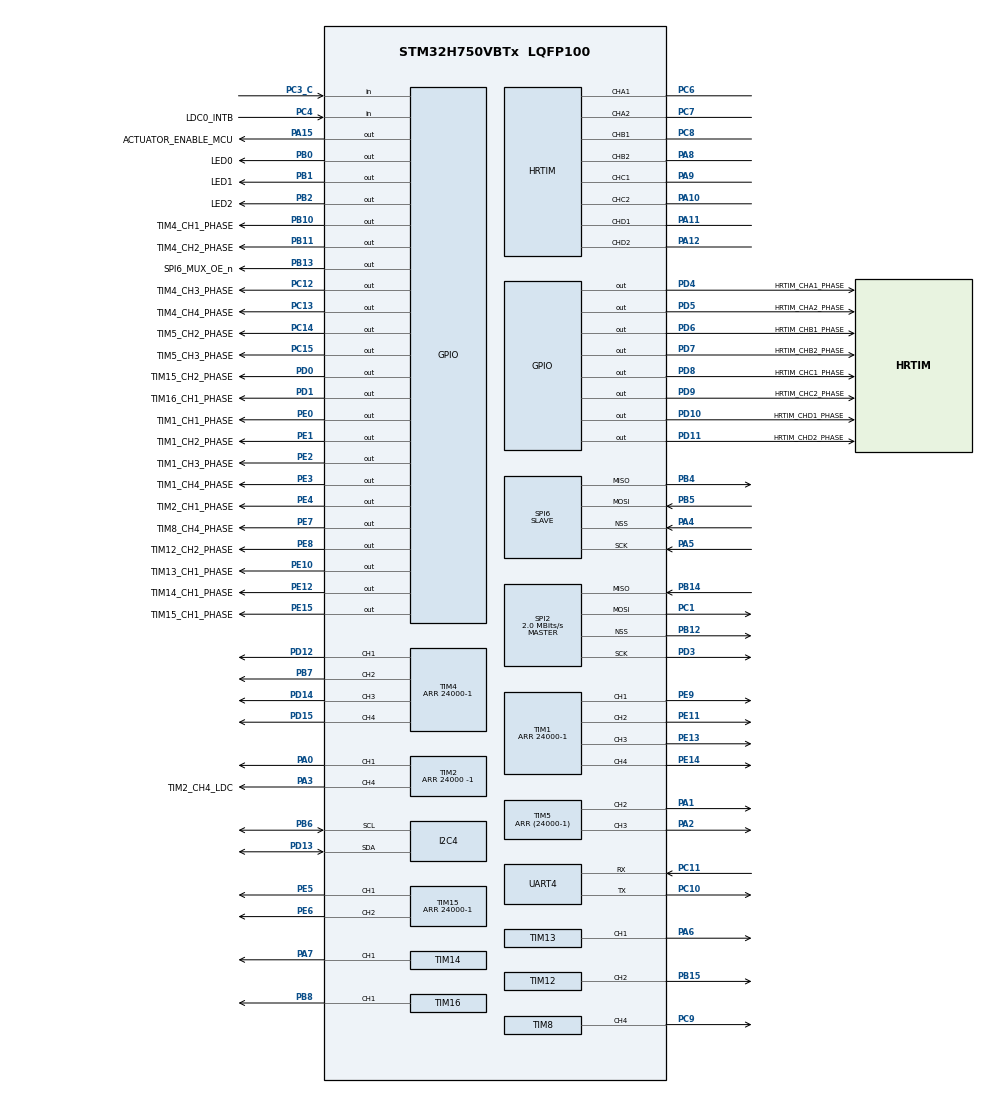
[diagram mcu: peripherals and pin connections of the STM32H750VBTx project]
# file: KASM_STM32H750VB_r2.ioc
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CRC.CRCLength=CRC_POLYLENGTH_16B
CRC.DefaultInitValueUse=DEFAULT_INIT_VALUE_DISABLE
CRC.DefaultPolynomialUse=DEFAULT_POLYNOMIAL_DISABLE
HRTIM.CompareUnit1-Output_TA1TA2=HRTIM_COMPAREUNIT_1
HRTIM.CompareUnit1-Output_TB1TB2=HRTIM_COMPAREUNIT_1
HRTIM.CompareUnit1-Output_TC1TC2=HRTIM_COMPAREUNIT_1
HRTIM.CompareUnit1-Output_TD1TD2=HRTIM_COMPAREUNIT_1
HRTIM.CompareUnit2-Output_TA1TA2=HRTIM_COMPAREUNIT_2
HRTIM.CompareUnit2-Output_TB1TB2=HRTIM_COMPAREUNIT_2
HRTIM.CompareUnit2-Output_TC1TC2=HRTIM_COMPAREUNIT_2
HRTIM.CompareUnit2-Output_TD1TD2=HRTIM_COMPAREUNIT_2
HRTIM.CompareValue1-Output_TA1TA2=(24000-1)/1000
HRTIM.CompareValue1-Output_TB1TB2=(24000-1)/1000
HRTIM.CompareValue1-Output_TC1TC2=(24000 -1)/1000
HRTIM.CompareValue1-Output_TD1TD2=(24000-1)/1000
HRTIM.CompareValue2-Output_TA1TA2=(24000-1)/1000
HRTIM.CompareValue2-Output_TB1TB2=(24000-1)/1000
HRTIM.CompareValue2-Output_TC1TC2=(24000-1)/1000
HRTIM.CompareValue2-Output_TD1TD2=(24000-1)/1000
HRTIM.Configuration_TD=Waveform
HRTIM.Event_EEV1=HRTIM_EVENT_1
HRTIM.NumberResetSource1-Output_TA1TA2=1
HRTIM.NumberResetSource1-Output_TB1TB2=1
HRTIM.NumberResetSource1-Output_TC1TC2=1
HRTIM.NumberResetSource1-Output_TD1TD2=1
HRTIM.NumberResetSource2_TA=1
HRTIM.NumberResetSource2_TB=1
HRTIM.NumberResetSource2_TC=1
HRTIM.NumberResetSource2_TD=1
HRTIM.NumberResetTrigger-Output_TA1TA2=1
HRTIM.NumberResetTrigger-Output_TB1TB2=1
HRTIM.NumberResetTrigger-Output_TC1TC2=1
HRTIM.NumberResetTrigger-Output_TD1TD2=1
HRTIM.NumberSetSource1-Output_TA1TA2=2
HRTIM.NumberSetSource1-Output_TB1TB2=2
HRTIM.NumberSetSource1-Output_TC1TC2=2
HRTIM.NumberSetSource1-Output_TD1TD2=1
HRTIM.NumberSetSource2_TA=2
HRTIM.NumberSetSource2_TB=2
HRTIM.NumberSetSource2_TC=1
HRTIM.NumberSetSource2_TD=1
HRTIM.NumberUpdateTrigger-Output_TA1TA2=0
HRTIM.Periode_TA=24000 -1
HRTIM.Periode_TB=24000-1
HRTIM.Periode_TC=24000-1
HRTIM.Periode_TD=24000 -1
HRTIM.PreloadEnable-Output_TA1TA2=HRTIM_PRELOAD_ENABLED
HRTIM.PreloadEnable-Output_TB1TB2=HRTIM_PRELOAD_ENABLED
HRTIM.PreloadEnable-Output_TC1TC2=HRTIM_PRELOAD_ENABLED
HRTIM.PreloadEnable-Output_TD1TD2=HRTIM_PRELOAD_ENABLED
HRTIM.PrescalerRatio_TA=HRTIM_PRESCALERRATIO_DIV1
HRTIM.ResetOutput1_Source1-Output_TA1TA2=HRTIM_OUTPUTRESET_TIMCMP1
HRTIM.ResetOutput1_Source1-Output_TB1TB2=HRTIM_OUTPUTRESET_TIMCMP1
HRTIM.ResetOutput1_Source1-Output_TC1TC2=HRTIM_OUTPUTRESET_TIMCMP1
HRTIM.ResetOutput1_Source1-Output_TD1TD2=HRTIM_OUTPUTRESET_TIMCMP1
HRTIM.ResetOutput2_Source1-Output_TA1TA2=HRTIM_OUTPUTRESET_TIMCMP2
HRTIM.ResetOutput2_Source1-Output_TB1TB2=HRTIM_OUTPUTRESET_TIMCMP2
HRTIM.ResetOutput2_Source1-Output_TC1TC2=HRTIM_OUTPUTRESET_TIMCMP2
HRTIM.ResetOutput2_Source1-Output_TD1TD2=HRTIM_OUTPUTRESET_TIMCMP2
HRTIM.ResetTrigger1-Output_TA1TA2=HRTIM_TIMRESETTRIGGER_EEV_1
HRTIM.ResetTrigger1-Output_TB1TB2=HRTIM_TIMRESETTRIGGER_EEV_1
HRTIM.ResetTrigger1-Output_TC1TC2=HRTIM_TIMRESETTRIGGER_EEV_1
HRTIM.ResetTrigger1-Output_TD1TD2=HRTIM_TIMRESETTRIGGER_EEV_1
HRTIM.ResetUpdate-Output_TA1TA2=HRTIM_TIMUPDATEONRESET_ENABLED
HRTIM.ResetUpdate-Output_TB1TB2=HRTIM_TIMUPDATEONRESET_ENABLED
HRTIM.ResetUpdate-Output_TC1TC2=HRTIM_TIMUPDATEONRESET_ENABLED
HRTIM.ResetUpdate-Output_TD1TD2=HRTIM_TIMUPDATEONRESET_ENABLED
HRTIM.Sensitivity_EEV1=HRTIM_EVENTSENSITIVITY_RISINGEDGE
HRTIM.SetOutput1_Source1-Output_TA1TA2=HRTIM_OUTPUTSET_EEV_1
HRTIM.SetOutput1_Source1-Output_TB1TB2=HRTIM_OUTPUTSET_RESYNC
HRTIM.SetOutput1_Source1-Output_TC1TC2=HRTIM_OUTPUTSET_TIMPER
HRTIM.SetOutput1_Source1-Output_TD1TD2=HRTIM_OUTPUTSET_TIMPER
HRTIM.SetOutput1_Source2-Output_TA1TA2=HRTIM_OUTPUTSET_TIMPER
HRTIM.SetOutput1_Source2-Output_TB1TB2=HRTIM_OUTPUTSET_TIMPER
HRTIM.SetOutput1_Source2-Output_TC1TC2=HRTIM_OUTPUTSET_RESYNC
HRTIM.SetOutput2_Source1-Output_TA1TA2=HRTIM_OUTPUTSET_TIMPER
HRTIM.SetOutput2_Source1-Output_TB1TB2=HRTIM_OUTPUTSET_RESYNC
HRTIM.SetOutput2_Source1-Output_TC1TC2=HRTIM_OUTPUTSET_TIMPER
HRTIM.SetOutput2_Source1-Output_TD1TD2=HRTIM_OUTPUTSET_TIMPER
HRTIM.SetOutput2_Source2-Output_TA1TA2=HRTIM_OUTPUTSET_EEV_1
HRTIM.SetOutput2_Source2-Output_TB1TB2=HRTIM_OUTPUTSET_TIMPER
HRTIM.Source_EEV1=HRTIM_EVENTSRC_3
I2C4.Timing=0x307075B1
Mcu.Family=STM32H7
Mcu.Name=STM32H750VBTx
Mcu.Package=LQFP100
NVIC.PriorityGroup=NVIC_PRIORITYGROUP_4
NVIC.SPI6_IRQn=true\:1\:0\:true\:false\:true\:true\:true\:true
NVIC.TIM1_UP_IRQn=true\:0\:0\:false\:false\:true\:true\:true\:true
NVIC.UART4_IRQn=true\:2\:0\:true\:false\:true\:true\:true\:true
PA0.Signal=S_TIM2_CH1_ETR
PA1.Signal=S_TIM5_CH2
PA10.Mode=Output_TC1TC2
PA10.Signal=HRTIM_CHC2
PA11.Mode=Output_TD1TD2
PA11.Signal=HRTIM_CHD1
PA12.Mode=Output_TD1TD2
PA12.Signal=HRTIM_CHD2
PA13\ (JTMS/SWDIO).Mode=Trace_Asynchronous_SW
PA13\ (JTMS/SWDIO).Signal=DEBUG_JTMS-SWDIO
PA14\ (JTCK/SWCLK).Mode=Trace_Asynchronous_SW
PA14\ (JTCK/SWCLK).Signal=DEBUG_JTCK-SWCLK
PA15\ (JTDI).GPIO_Label=ACTUATOR_ENABLE_MCU
PA15\ (JTDI).Signal=GPIO_Output
PA2.Signal=S_TIM5_CH3
PA3.GPIO_Label=TIM2_CH4_LDC
PA3.Signal=S_TIM2_CH4
PA4.Mode=NSS_Signal_Hard_Input
PA4.Signal=SPI6_NSS
PA5.Mode=Full_Duplex_Slave
PA5.Signal=SPI6_SCK
PA6.Signal=S_TIM13_CH1
PA7.Signal=S_TIM14_CH1
PA8.Mode=Output_TB1TB2
PA8.Signal=HRTIM_CHB2
PA9.Mode=Output_TC1TC2
PA9.Signal=HRTIM_CHC1
PB0.GPIO_Label=LED0
PB0.Signal=GPIO_Output
PB1.GPIO_Label=LED1
PB1.Signal=GPIO_Output
PB10.GPIO_Label=TIM4_CH1_PHASE
PB10.Signal=GPIO_Output
PB11.GPIO_Label=TIM4_CH2_PHASE
PB11.Signal=GPIO_Output
PB12.Mode=NSS_Signal_Hard_Output
PB12.Signal=SPI2_NSS
PB13.GPIO_Label=SPI6_MUX_OE_n
PB13.Signal=GPIO_Output
PB14.Mode=Full_Duplex_Master
PB14.Signal=SPI2_MISO
PB15.Signal=S_TIM12_CH2
PB2.GPIO_Label=LED2
PB2.Signal=GPIO_Output
PB3\ (JTDO/TRACESWO).Mode=Trace_Asynchronous_SW
PB3\ (JTDO/TRACESWO).Signal=DEBUG_JTDO-SWO
PB4\ (NJTRST).Mode=Full_Duplex_Slave
PB4\ (NJTRST).Signal=SPI6_MISO
PB5.Mode=Full_Duplex_Slave
PB5.Signal=SPI6_MOSI
PB6.Mode=I2C
PB6.Signal=I2C4_SCL
PB7.Signal=S_TIM4_CH2
PB8.Signal=S_TIM16_CH1
PC0.Signal=ADCx_INP10
PC1.Mode=Full_Duplex_Master
PC1.Signal=SPI2_MOSI
PC10.Mode=Asynchronous
PC10.Signal=UART4_TX
PC11.Mode=Asynchronous
PC11.Signal=UART4_RX
PC12.GPIO_Label=TIM4_CH3_PHASE
PC12.Signal=GPIO_Output
PC13.GPIO_Label=TIM4_CH4_PHASE
PC13.Signal=GPIO_Output
PC14-OSC32_IN\ (OSC32_IN).GPIO_Label=TIM5_CH2_PHASE
PC14-OSC32_IN\ (OSC32_IN).Signal=GPIO_Output
PC15-OSC32_OUT\ (OSC32_OUT).GPIO_Label=TIM5_CH3_PHASE
PC15-OSC32_OUT\ (OSC32_OUT).Signal=GPIO_Output
PC3_C.Signal=GPIO_Input
PC4.GPIO_Label=LDC0_INTB
PC4.Signal=GPIO_Input
PC6.Mode=Output_TA1TA2
PC6.Signal=HRTIM_CHA1
PC7.Mode=Output_TA1TA2
PC7.Signal=HRTIM_CHA2
PC8.Mode=Output_TB1TB2
PC8.Signal=HRTIM_CHB1
PC9.Signal=S_TIM8_CH4
PD0.GPIO_Label=TIM15_CH2_PHASE
PD0.Signal=GPIO_Output
PD1.GPIO_Label=TIM16_CH1_PHASE
PD1.Signal=GPIO_Output
PD10.GPIO_Label=HRTIM_CHD1_PHASE
PD10.Signal=GPIO_Output
PD11.GPIO_Label=HRTIM_CHD2_PHASE
PD11.Signal=GPIO_Output
PD12.Signal=S_TIM4_CH1
PD13.Mode=I2C
PD13.Signal=I2C4_SDA
PD14.Signal=S_TIM4_CH3
PD15.Signal=S_TIM4_CH4
PD3.Mode=Full_Duplex_Master
PD3.Signal=SPI2_SCK
PD4.GPIO_Label=HRTIM_CHA1_PHASE
PD4.Signal=GPIO_Output
PD5.GPIO_Label=HRTIM_CHA2_PHASE
PD5.Signal=GPIO_Output
PD6.GPIO_Label=HRTIM_CHB1_PHASE
PD6.Signal=GPIO_Output
PD7.GPIO_Label=HRTIM_CHB2_PHASE
PD7.Signal=GPIO_Output
PD8.GPIO_Label=HRTIM_CHC1_PHASE
PD8.Signal=GPIO_Output
PD9.GPIO_Label=HRTIM_CHC2_PHASE
PD9.Signal=GPIO_Output
PE0.GPIO_Label=TIM1_CH1_PHASE
PE0.Signal=GPIO_Output
PE1.GPIO_Label=TIM1_CH2_PHASE
PE1.Signal=GPIO_Output
PE10.GPIO_Label=TIM13_CH1_PHASE
PE10.Signal=GPIO_Output
PE11.Signal=S_TIM1_CH2
PE12.GPIO_Label=TIM14_CH1_PHASE
PE12.Signal=GPIO_Output
PE13.Signal=S_TIM1_CH3
PE14.Signal=S_TIM1_CH4
PE15.GPIO_Label=TIM15_CH1_PHASE
PE15.Signal=GPIO_Output
PE2.GPIO_Label=TIM1_CH3_PHASE
PE2.Signal=GPIO_Output
PE3.GPIO_Label=TIM1_CH4_PHASE
PE3.Signal=GPIO_Output
PE4.GPIO_Label=TIM2_CH1_PHASE
PE4.Signal=GPIO_Output
PE5.Signal=S_TIM15_CH1
PE6.Signal=S_TIM15_CH2
PE7.GPIO_Label=TIM8_CH4_PHASE
PE7.Signal=GPIO_Output
PE8.GPIO_Label=TIM12_CH2_PHASE
PE8.Signal=GPIO_Output
PE9.Signal=S_TIM1_CH1
PH0-OSC_IN\ (PH0).Mode=HSE-External-Oscillator
PH0-OSC_IN\ (PH0).Signal=RCC_OSC_IN
PH1-OSC_OUT\ (PH1).Mode=HSE-External-Oscillator
PH1-OSC_OUT\ (PH1).Signal=RCC_OSC_OUT
ProjectManager.HeapSize=0x200
ProjectManager.StackSize=0x400
ProjectManager.TargetToolchain=STM32CubeIDE
RCC.ADCFreq_Value=75000000
RCC.APB1Freq_Value=120000000
RCC.APB2Freq_Value=120000000
RCC.APB3Freq_Value=120000000
RCC.APB4Freq_Value=120000000
RCC.CortexFreq_Value=480000000
RCC.D1PPRE=RCC_APB3_DIV2
RCC.D2PPRE1=RCC_APB1_DIV2
RCC.D2PPRE2=RCC_APB2_DIV2
RCC.D3PPRE=RCC_APB4_DIV2
RCC.DIVM1=2
RCC.DIVM2=2
RCC.DIVN1=80
RCC.DIVN2=12
RCC.DIVQ1=15
RCC.HCLKFreq_Value=240000000
RCC.HPRE=RCC_HCLK_DIV2
RCC.HSE_VALUE=24000000
RCC.PLL2FRACN=4096
RCC.PLL3FRACN=0
RCC.PLLFRACN=0
RCC.PLLSourceVirtual=RCC_PLLSOURCE_HSE
RCC.SYSCLKFreq_VALUE=480000000
RCC.SYSCLKSource=RCC_SYSCLKSOURCE_PLLCLK
RCC.USBFreq_Value=64000000
SH.ADCx_INP10.0=ADC2_INP10
SH.S_TIM12_CH2.0=TIM12_CH2,PWM Generation2 CH2
SH.S_TIM13_CH1.0=TIM13_CH1,PWM Generation1 CH1
SH.S_TIM14_CH1.0=TIM14_CH1,PWM Generation1 CH1
SH.S_TIM15_CH1.0=TIM15_CH1,PWM Generation1 CH1
SH.S_TIM15_CH2.0=TIM15_CH2,PWM Generation2 CH2
SH.S_TIM16_CH1.0=TIM16_CH1,PWM Generation1 CH1
SH.S_TIM1_CH1.0=TIM1_CH1,PWM Generation1 CH1
SH.S_TIM1_CH2.0=TIM1_CH2,PWM Generation2 CH2
SH.S_TIM1_CH3.0=TIM1_CH3,PWM Generation3 CH3
SH.S_TIM1_CH4.0=TIM1_CH4,PWM Generation4 CH4
SH.S_TIM2_CH1_ETR.0=TIM2_CH1,PWM Generation1 CH1
SH.S_TIM2_CH4.0=TIM2_CH4,PWM Generation4 CH4
SH.S_TIM4_CH1.0=TIM4_CH1,PWM Generation1 CH1
SH.S_TIM4_CH2.0=TIM4_CH2,PWM Generation2 CH2
SH.S_TIM4_CH3.0=TIM4_CH3,PWM Generation3 CH3
SH.S_TIM4_CH4.0=TIM4_CH4,PWM Generation4 CH4
SH.S_TIM5_CH2.0=TIM5_CH2,PWM Generation2 CH2
SH.S_TIM5_CH3.0=TIM5_CH3,PWM Generation3 CH3
SH.S_TIM8_CH4.0=TIM8_CH4,PWM Generation4 CH4
SPI2.BaudRatePrescaler=SPI_BAUDRATEPRESCALER_32
SPI2.CalculateBaudRate=2.0 MBits/s
SPI2.DataSize=SPI_DATASIZE_8BIT
SPI2.Direction=SPI_DIRECTION_2LINES
SPI2.Mode=SPI_MODE_MASTER
SPI2.VirtualNSS=VM_NSSHARD
SPI2.VirtualType=VM_MASTER
SPI6.DataSize=SPI_DATASIZE_8BIT
SPI6.Direction=SPI_DIRECTION_2LINES
SPI6.Mode=SPI_MODE_SLAVE
SPI6.VirtualNSS=VM_NSSHARD
SPI6.VirtualType=VM_SLAVE
TIM1.AutoReloadPreload=TIM_AUTORELOAD_PRELOAD_ENABLE
TIM1.Channel-PWM\ Generation1\ CH1=TIM_CHANNEL_1
TIM1.Channel-PWM\ Generation2\ CH2=TIM_CHANNEL_2
TIM1.Channel-PWM\ Generation3\ CH3=TIM_CHANNEL_3
TIM1.Channel-PWM\ Generation4\ CH4=TIM_CHANNEL_4
TIM1.Period=24000-1
TIM1.Pulse-PWM\ Generation1\ CH1=(24000-1)/1000
TIM1.Pulse-PWM\ Generation2\ CH2=(24000-1)/1000
TIM1.Pulse-PWM\ Generation3\ CH3=(24000-1)/1000
TIM1.Pulse-PWM\ Generation4\ CH4=(24000-1)/1000
TIM1.TIM_MasterOutputTrigger=TIM_TRGO_UPDATE
TIM1.TIM_MasterSlaveMode=TIM_MASTERSLAVEMODE_ENABLE
TIM12.AutoReloadPreload=TIM_AUTORELOAD_PRELOAD_ENABLE
TIM12.Channel-PWM\ Generation2\ CH2=TIM_CHANNEL_2
TIM12.Period=24000-1
TIM12.Pulse-PWM\ Generation2\ CH2=(24000-1)/1000
TIM13.Channel=TIM_CHANNEL_1
TIM13.Period=24000-1
TIM13.Pulse=(24000-1)/1000
TIM14.Channel=TIM_CHANNEL_1
TIM14.Period=24000-1
TIM14.Pulse=(24000-1)/1000
TIM15.Channel-PWM\ Generation1\ CH1=TIM_CHANNEL_1
TIM15.Channel-PWM\ Generation2\ CH2=TIM_CHANNEL_2
TIM15.Period=24000-1
TIM15.Pulse-PWM\ Generation1\ CH1=(24000-1)/1000
TIM15.Pulse-PWM\ Generation2\ CH2=(24000-1)/1000
TIM16.Channel=TIM_CHANNEL_1
TIM16.Period=24000-1
TIM16.Pulse=(24000-1)/1000
TIM2.Channel-PWM\ Generation1\ CH1=TIM_CHANNEL_1
TIM2.Channel-PWM\ Generation4\ CH4=TIM_CHANNEL_4
TIM2.Period=24000 -1
TIM2.Pulse-PWM\ Generation1\ CH1=(24000 -1)/1000
TIM2.Pulse-PWM\ Generation4\ CH4=(24000-1)/1000
TIM4.Channel-PWM\ Generation1\ CH1=TIM_CHANNEL_1
TIM4.Channel-PWM\ Generation2\ CH2=TIM_CHANNEL_2
TIM4.Channel-PWM\ Generation3\ CH3=TIM_CHANNEL_3
TIM4.Channel-PWM\ Generation4\ CH4=TIM_CHANNEL_4
TIM4.Period=24000-1
TIM4.Pulse-PWM\ Generation1\ CH1=(24000 -1)/1000
TIM4.Pulse-PWM\ Generation2\ CH2=(24000-1)/1000
TIM4.Pulse-PWM\ Generation3\ CH3=(24000-1)/1000
TIM4.Pulse-PWM\ Generation4\ CH4=(24000-1)/1000
TIM4.TIM_MasterOutputTrigger=TIM_TRGO_UPDATE
TIM5.AutoReloadPreload=TIM_AUTORELOAD_PRELOAD_ENABLE
TIM5.Channel-PWM\ Generation2\ CH2=TIM_CHANNEL_2
TIM5.Channel-PWM\ Generation3\ CH3=TIM_CHANNEL_3
TIM5.Period=(24000-1)
TIM5.Pulse-PWM\ Generation2\ CH2=(24000-1)/1000
TIM5.Pulse-PWM\ Generation3\ CH3=(24000-1)/1000
TIM8.AutoReloadPreload=TIM_AUTORELOAD_PRELOAD_ENABLE
TIM8.Channel-PWM\ Generation4\ CH4=TIM_CHANNEL_4
TIM8.Period=24000 -1
TIM8.Pulse-PWM\ Generation4\ CH4=(24000-1)/1000
UART4.FIFOMode=FIFOMODE_DISABLE
VP_CRC_VS_CRC.Mode=CRC_Activate
VP_LPTIM1_VS_LPTIM_counterModeInternalClock.Mode=Counts__internal_clock_event_00
VP_LPTIM2_VS_LPTIM_counterModeInternalClock.Mode=Counts__internal_clock_event_00
VP_LPTIM3_VS_LPTIM_counterModeInternalClock.Mode=Counts__internal_clock_event_00
VP_MEMORYMAP_VS_MEMORYMAP.Mode=CurAppReg
VP_TIM12_VS_ClockSourceITR.Mode=TriggerSource_ITR0
VP_TIM12_VS_ControllerModeReset.Mode=Reset Mode
VP_TIM13_VS_ClockSourceINT.Mode=Enable_Timer
VP_TIM14_VS_ClockSourceINT.Mode=Enable_Timer
VP_TIM15_VS_ClockSourceITR.Mode=TriggerSource_ITR0
VP_TIM15_VS_ControllerModeReset.Mode=Reset Mode
VP_TIM16_VS_ClockSourceINT.Mode=Enable_Timer
VP_TIM1_VS_ClockSourceINT.Mode=Internal
VP_TIM4_VS_ClockSourceINT.Mode=Internal
VP_TIM4_VS_ClockSourceITR.Mode=TriggerSource_ITR0
VP_TIM4_VS_ControllerModeReset.Mode=Reset Mode
VP_TIM5_VS_ClockSourceITR.Mode=TriggerSource_ITR0
VP_TIM5_VS_ControllerModeReset.Mode=Reset Mode
VP_TIM8_VS_ClockSourceITR.Mode=TriggerSource_ITR0
VP_TIM8_VS_ControllerModeReset.Mode=Reset Mode
board=custom

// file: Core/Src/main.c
/* USER CODE BEGIN Header */
/**
  ******************************************************************************
  * @file           : main.c
  * @brief          : Main program body
  ******************************************************************************
  * @attention
  *
  * Copyright (c) 2025 STMicroelectronics.
  * All rights reserved.
  *
  * This software is licensed under terms that can be found in the LICENSE file
  * in the root directory of this software component.
  * If no LICENSE file comes with this software, it is provided AS-IS.
  *
  ******************************************************************************
  */
/* USER CODE END Header */
#include "main.h"

/* USER CODE BEGIN Includes */
#include "circular_buffer.h"
#include "actuators.h"
#include "stdio.h"
#include "stdlib.h"
#include "string.h"

/* USER CODE END Includes */

/* USER CODE BEGIN PD */

#define TRUE 1
#define FALSE 0
#define BUFFER_SIZE 80
#define MINDUTYCYCLE 20
#define PERIOD (24000-1)
#define MAXDUTYCYCLE PERIOD
#define MICRON_1 1000
#define MICRON_10 10000
#define CMD_VEC_LENGTH (NUM_ACTUATORS * 2)
#define CMD_HDR_LENGTH 3
#define END1 0xe1
#define END2 0xe2
#define SPI_BUFFER_SIZE 1000
#define SPI_TICKS 10000
#define SPI_MSG_SIZE 54

/* USER CODE END PD */

CRC_HandleTypeDef hcrc;

HRTIM_HandleTypeDef hhrtim;

I2C_HandleTypeDef hi2c4;

LPTIM_HandleTypeDef hlptim1;
LPTIM_HandleTypeDef hlptim2;
LPTIM_HandleTypeDef hlptim3;

SPI_HandleTypeDef hspi2;
SPI_HandleTypeDef hspi6;

TIM_HandleTypeDef htim1;
TIM_HandleTypeDef htim2;
TIM_HandleTypeDef htim4;
TIM_HandleTypeDef htim5;
TIM_HandleTypeDef htim8;
TIM_HandleTypeDef htim12;
TIM_HandleTypeDef htim13;
TIM_HandleTypeDef htim14;
TIM_HandleTypeDef htim15;
TIM_HandleTypeDef htim16;

/* USER CODE BEGIN PV */

/* UART transmit and receive buffers */
circular_buffer_t rxbuf; /* UART receive buffer */
circular_buffer_t txbuf; /* UART transmit buffer */
circular_buffer_t *rxbuf_p = &rxbuf; /* UART receive buffer pointer */
circular_buffer_t *txbuf_p = &txbuf; /* UART transmit buffer pointer */

/* UART flags and signals */
int msg_recvd = FALSE;
//char msg_buffer[BUFFER_LENGTH];
int reading_rx_buffer = FALSE;
int writing_tx_buffer = FALSE;
int tx_collision = FALSE;
int rx_collision = FALSE;
volatile int rx_collision_count = 0;
volatile int tx_collision_count = 0;
volatile int cbuf_write_err = FALSE;

/* SPI circular RX buffer */
circular_buffer_t spirx_cbuf;
circular_buffer_t* spirx_cbuf_p = &spirx_cbuf; // buffer handle pointer

/* SPI test message and buffers */
uint8_t SPI_TX_buffer[SPI_MSG_SIZE] = {0};
uint8_t SPI_RX_buffer[SPI_BUFFER_SIZE] = {0};

/* SPI flags and signals */
int spi_packet_rcvd = FALSE;
int spi_counter_expired = FALSE;

/* Period timer flag */
uint32_t tick_counter = 0;  // use the period counter as a clock
uint8_t ctrl_tmr_expired = FALSE;

/* Command reference vector */
union command {
	int16_t vals[NUM_ACTUATORS];  //displacement commands in nanometers
	uint8_t bytes[NUM_ACTUATORS *2];  // byte equivalents
} reference;
union command* ref_p = &reference;

static int16_t cmd_ref[NUM_ACTUATORS] = {0};  //displacement commands in nanometers

/* TODO */
/* We need the actual bytes to transmit, not the short ints-->either set up a union, or calculate the bytes externally */
static int16_t rnd_vals[NUM_ACTUATORS] = {-850, -50, 922, -10000, -895, 29, 175, 586, 259, 232, 381, -190, 447, 163, -1012, 863, 619, -861, 213, 390, -83, 592, 903, -845, 313, -833};  //random displacement commands in nanometers

uint8_t cmd_bytes[NUM_ACTUATORS * 2] = {0};
uint8_t new_cmd_ready = FALSE;

/* actuators */
actuator_t actuators[NUM_ACTUATORS];

typedef enum serial_receive_state_t{
	STORE_BYTE,
	CHECK_FOR_END
}serial_receive_state_t;

uint16_t test_data[2] = {0};

/* USER CODE END PV */

void SystemClock_Config(void);
static void MX_GPIO_Init(void);
static void MX_HRTIM_Init(void);
static void MX_I2C4_Init(void);
static void MX_LPTIM1_Init(void);
static void MX_LPTIM2_Init(void);
static void MX_LPTIM3_Init(void);
static void MX_SPI2_Init(void);
static void MX_TIM1_Init(void);
static void MX_TIM2_Init(void);
static void MX_TIM4_Init(void);
static void MX_TIM5_Init(void);
static void MX_TIM8_Init(void);
static void MX_TIM12_Init(void);
static void MX_TIM13_Init(void);
static void MX_TIM14_Init(void);
static void MX_TIM15_Init(void);
static void MX_TIM16_Init(void);
static void MX_UART4_Init(void);
static void MX_SPI6_Init(void);
static void MX_CRC_Init(void);
/* USER CODE BEGIN PFP */

/**
 * @function : UART_parse_message
 * @brief : reads the message from the rx buffer and puts it into module level message buffer
 * @param :  none
 * @return : none
 * @author : Aaron Hunter
 */
static void UART_parse_message();

/**
 * @function : UART_print(char* buf, int length)
 * @brief : writes a buffer to the tx_buffer and triggers a UART TX
 * @param : buffer pointer
 * @param : buffer length
 * @return : none
 * @author : Aaron Hunter
 */
static void UART_print(char* buf, int length);

/**
 * @function : init_channels
 * @brief : initializes all the PWM channels
 * @param :  none
 * @return : none
 * @author : Aaron Hunter
 */
static void init_channels(void);

/**
 * @function : init_actuators
 * @brief : Creates and populates actuator array
 * @param :  none
 * @return : none
 * @author : Aaron Hunter
 */
static void init_actuators(void);

/**
 * @function : update_commands
 * @brief : sets the new actuator command targets
 * @return none
 * @author Aaron Hunter
 */
static void update_commands(void);

/**
 * @function calc_dutycycle(cmd)
 * @param cmd
 * @return dutycycle
 * @authoer Aaron Hunter
 */
uint16_t calc_dutycycle(int16_t cmd);

/**
 * @function : run_RX_state_machine
 * @brief : parses external command messages
 * @param byte : received byte
 * @return none
 * @author Aaron Hunter
 * */
void run_RX_state_machine(uint8_t byte);

/**
 * @function : run_SPI_RX_state_machine
 * @brief : parses external SPI command messages
 * @param byte : received byte
 * @return none
 * @author Aaron Hunter
 * */
void run_SPI_RX_state_machine(uint8_t byte);

/* USER CODE END PFP */

int main(void)
{

  /* USER CODE BEGIN 1 */

	/* init all actuators to a small displacement */
	int i = {0};
	for(i = 0; i < NUM_ACTUATORS; i++){
		reference.vals[i] = MICRON_10;
	}
	new_cmd_ready = TRUE; // tell main to update the actuator dutycycles

	test_data[0] = 0xdead;
	test_data[1] = 0xbeef;
  /* USER CODE END 1 */

  /* MCU Configuration--------------------------------------------------------*/

  /* Reset of all peripherals, Initializes the Flash interface and the Systick. */
  HAL_Init();

  /* USER CODE BEGIN Init */

  /* initialize the circular buffers */
  init_buffer(rxbuf_p);
  init_buffer(txbuf_p);
  init_buffer(spirx_cbuf_p);

  /* USER CODE END Init */

  /* Configure the system clock */
  SystemClock_Config();

  /* Initialize all configured peripherals */
  MX_GPIO_Init();
  MX_HRTIM_Init();
  MX_I2C4_Init();
  MX_LPTIM1_Init();
  MX_LPTIM2_Init();
  MX_LPTIM3_Init();
  MX_SPI2_Init();
  MX_TIM1_Init();
  MX_TIM2_Init();
  MX_TIM4_Init();
  MX_TIM5_Init();
  MX_TIM8_Init();
  MX_TIM12_Init();
  MX_TIM13_Init();
  MX_TIM14_Init();
  MX_TIM15_Init();
  MX_TIM16_Init();
  MX_UART4_Init();
  MX_SPI6_Init();
  MX_CRC_Init();
  /* USER CODE BEGIN 2 */

  init_channels(); // start PWM generation
  init_actuators(); // set up the actuators
  HAL_GPIO_WritePin(ACTUATOR_ENABLE_MCU_GPIO_Port, ACTUATOR_ENABLE_MCU_Pin, GPIO_PIN_SET); // Turn on actuator power

  /* Say hello to the outside world */
  uint8_t msg[BUFFER_SIZE];
  int msg_length = 0;
  msg_length = sprintf((char *) msg,"KASM Application Starting \r\n");
  UART_print((char *) msg, msg_length);

  SPI_TX_buffer[0] = 0xaa;
  HAL_SPI_TransmitReceive_IT(&hspi6, SPI_TX_buffer, SPI_RX_buffer, SPI_MSG_SIZE);

  /* USER CODE END 2 */

  /* Infinite loop */
  /* USER CODE BEGIN WHILE */
  while (1)
  {
	  /* diagnostics for the interrupts to be removed later */
	  HAL_GPIO_WritePin(LED0_GPIO_Port, LED0_Pin,GPIO_PIN_RESET);
	  HAL_GPIO_WritePin(LED2_GPIO_Port, LED2_Pin,GPIO_PIN_RESET);
	  if(msg_recvd == TRUE){
		  UART_parse_message();
		  msg_recvd = FALSE;
	  }

	  if(ctrl_tmr_expired == TRUE){
		  tick_counter++;
		  if (tick_counter % SPI_TICKS == 0) {
			  spi_counter_expired = TRUE;
		  }
		  if( new_cmd_ready == TRUE){ //only update commands on change
			  update_commands();// update command targets
			  new_cmd_ready = FALSE;
		  }
		  ctrl_tmr_expired = FALSE; //reset timer
	  }

	  /* check for errors to the UART circular buffers */
	  if(cbuf_write_err == TRUE){
		  msg_length = sprintf(msg, "Message read error ");
		  UART_print(msg,msg_length);
		  cbuf_write_err = FALSE;
	  }

	  if(spi_packet_rcvd == TRUE){
		  HAL_GPIO_WritePin(LED1_GPIO_Port, LED1_Pin,GPIO_PIN_RESET);

#ifdef SPI_TESTING
		  int i = {0};
		  for(i = 0; i < SPI_MSG_SIZE; i++){
			  msg_length = sprintf((char *) msg,"%x ",SPI_RX_buffer[i]);
			  UART_print((char *) msg, msg_length);
		  }
		  msg_length = sprintf((char *) msg,"\r\n");
		  UART_print((char *) msg, msg_length);
#endif

		  // check crc for transmission errors
		  uint32_t crc_val = HAL_CRC_Calculate(&hcrc, (uint32_t*) &SPI_RX_buffer,SPI_MSG_SIZE/2);

#ifdef SPI_TESTING
		  msg_length = sprintf((char *) msg,"CRC check %x\r\n", crc_val);
		  UART_print((char *) msg, msg_length);
#endif

		  if(crc_val == 0){
			  msg_length = sprintf((char *) msg,"Valid SPI command vector received \r\n");
			  UART_print((char *) msg, msg_length);
			  // copy memory into command vector
			  memcpy(reference.vals, &SPI_RX_buffer, NUM_ACTUATORS*(sizeof(int16_t)));
			  // inform main of a new command
			  new_cmd_ready = TRUE;
		  }

		  // restart SPI bus
		  HAL_SPI_TransmitReceive_IT(&hspi6, SPI_TX_buffer, SPI_RX_buffer, SPI_MSG_SIZE);

		  spi_packet_rcvd = FALSE; // reset SPI packet flag
	  }

    /* USER CODE END WHILE */

  }
}

void SystemClock_Config(void)
{
  RCC_OscInitTypeDef RCC_OscInitStruct = {0};
  RCC_ClkInitTypeDef RCC_ClkInitStruct = {0};

  /** Supply configuration update enable
  */
  HAL_PWREx_ConfigSupply(PWR_LDO_SUPPLY);

  /** Configure the main internal regulator output voltage
  */
  __HAL_PWR_VOLTAGESCALING_CONFIG(PWR_REGULATOR_VOLTAGE_SCALE0);

  while(!__HAL_PWR_GET_FLAG(PWR_FLAG_VOSRDY)) {}

  /** Initializes the RCC Oscillators according to the specified parameters
  * in the RCC_OscInitTypeDef structure.
  */
  RCC_OscInitStruct.OscillatorType = RCC_OSCILLATORTYPE_HSE;
  RCC_OscInitStruct.HSEState = RCC_HSE_ON;
  RCC_OscInitStruct.PLL.PLLState = RCC_PLL_ON;
  RCC_OscInitStruct.PLL.PLLSource = RCC_PLLSOURCE_HSE;
  RCC_OscInitStruct.PLL.PLLM = 2;
  RCC_OscInitStruct.PLL.PLLN = 80;
  RCC_OscInitStruct.PLL.PLLP = 2;
  RCC_OscInitStruct.PLL.PLLQ = 15;
  RCC_OscInitStruct.PLL.PLLR = 2;
  RCC_OscInitStruct.PLL.PLLRGE = RCC_PLL1VCIRANGE_3;
  RCC_OscInitStruct.PLL.PLLVCOSEL = RCC_PLL1VCOWIDE;
  RCC_OscInitStruct.PLL.PLLFRACN = 0;
  if (HAL_RCC_OscConfig(&RCC_OscInitStruct) != HAL_OK)
  {
    Error_Handler();
  }

  /** Initializes the CPU, AHB and APB buses clocks
  */
  RCC_ClkInitStruct.ClockType = RCC_CLOCKTYPE_HCLK|RCC_CLOCKTYPE_SYSCLK
                              |RCC_CLOCKTYPE_PCLK1|RCC_CLOCKTYPE_PCLK2
                              |RCC_CLOCKTYPE_D3PCLK1|RCC_CLOCKTYPE_D1PCLK1;
  RCC_ClkInitStruct.SYSCLKSource = RCC_SYSCLKSOURCE_PLLCLK;
  RCC_ClkInitStruct.SYSCLKDivider = RCC_SYSCLK_DIV1;
  RCC_ClkInitStruct.AHBCLKDivider = RCC_HCLK_DIV2;
  RCC_ClkInitStruct.APB3CLKDivider = RCC_APB3_DIV2;
  RCC_ClkInitStruct.APB1CLKDivider = RCC_APB1_DIV2;
  RCC_ClkInitStruct.APB2CLKDivider = RCC_APB2_DIV2;
  RCC_ClkInitStruct.APB4CLKDivider = RCC_APB4_DIV2;

  if (HAL_RCC_ClockConfig(&RCC_ClkInitStruct, FLASH_LATENCY_4) != HAL_OK)
  {
    Error_Handler();
  }
}

static void MX_CRC_Init(void)
{

  hcrc.Instance = CRC;
  hcrc.Init.DefaultPolynomialUse = DEFAULT_POLYNOMIAL_DISABLE;
  hcrc.Init.DefaultInitValueUse = DEFAULT_INIT_VALUE_DISABLE;
  hcrc.Init.GeneratingPolynomial = 15717;
  hcrc.Init.CRCLength = CRC_POLYLENGTH_16B;
  hcrc.Init.InitValue = 65535;
  hcrc.Init.InputDataInversionMode = CRC_INPUTDATA_INVERSION_NONE;
  hcrc.Init.OutputDataInversionMode = CRC_OUTPUTDATA_INVERSION_DISABLE;
  hcrc.InputDataFormat = CRC_INPUTDATA_FORMAT_HALFWORDS;
  if (HAL_CRC_Init(&hcrc) != HAL_OK)
  {
    Error_Handler();
  }
  /* USER CODE BEGIN CRC_Init 2 */
  hcrc.Instance = CRC;
  hcrc.Init.DefaultPolynomialUse = DEFAULT_POLYNOMIAL_DISABLE;
  hcrc.Init.DefaultInitValueUse = DEFAULT_INIT_VALUE_DISABLE;
  hcrc.Init.GeneratingPolynomial = 15717;
  hcrc.Init.CRCLength = CRC_POLYLENGTH_16B;
  hcrc.Init.InitValue = 65535;
  hcrc.Init.InputDataInversionMode = CRC_INPUTDATA_INVERSION_NONE;
  hcrc.Init.OutputDataInversionMode = CRC_OUTPUTDATA_INVERSION_DISABLE;
  hcrc.InputDataFormat = CRC_INPUTDATA_FORMAT_HALFWORDS;
  if (HAL_CRC_Init(&hcrc) != HAL_OK)
  {
    Error_Handler();
  }

  /* USER CODE END CRC_Init 2 */

}

static void MX_HRTIM_Init(void)
{

  HRTIM_EventCfgTypeDef pEventCfg = {0};
  HRTIM_TimeBaseCfgTypeDef pTimeBaseCfg = {0};
  HRTIM_TimerCfgTypeDef pTimerCfg = {0};
  HRTIM_CompareCfgTypeDef pCompareCfg = {0};
  HRTIM_OutputCfgTypeDef pOutputCfg = {0};

  hhrtim.Instance = HRTIM1;
  hhrtim.Init.HRTIMInterruptResquests = HRTIM_IT_NONE;
  hhrtim.Init.SyncOptions = HRTIM_SYNCOPTION_NONE;
  if (HAL_HRTIM_Init(&hhrtim) != HAL_OK)
  {
    Error_Handler();
  }
  if (HAL_HRTIM_EventPrescalerConfig(&hhrtim, HRTIM_EVENTPRESCALER_DIV1) != HAL_OK)
  {
    Error_Handler();
  }
  pEventCfg.Source = HRTIM_EVENTSRC_3;
  pEventCfg.Polarity = HRTIM_EVENTPOLARITY_HIGH;
  pEventCfg.Sensitivity = HRTIM_EVENTSENSITIVITY_RISINGEDGE;
  pEventCfg.FastMode = HRTIM_EVENTFASTMODE_DISABLE;
  if (HAL_HRTIM_EventConfig(&hhrtim, HRTIM_EVENT_1, &pEventCfg) != HAL_OK)
  {
    Error_Handler();
  }
  pTimeBaseCfg.Period = 24000 -1;
  pTimeBaseCfg.RepetitionCounter = 0x00;
  pTimeBaseCfg.PrescalerRatio = HRTIM_PRESCALERRATIO_DIV1;
  pTimeBaseCfg.Mode = HRTIM_MODE_CONTINUOUS;
  if (HAL_HRTIM_TimeBaseConfig(&hhrtim, HRTIM_TIMERINDEX_TIMER_A, &pTimeBaseCfg) != HAL_OK)
  {
    Error_Handler();
  }
  pTimerCfg.InterruptRequests = HRTIM_TIM_IT_NONE;
  pTimerCfg.DMARequests = HRTIM_TIM_DMA_NONE;
  pTimerCfg.DMASrcAddress = 0x0000;
  pTimerCfg.DMADstAddress = 0x0000;
  pTimerCfg.DMASize = 0x1;
  pTimerCfg.HalfModeEnable = HRTIM_HALFMODE_DISABLED;
  pTimerCfg.StartOnSync = HRTIM_SYNCSTART_DISABLED;
  pTimerCfg.ResetOnSync = HRTIM_SYNCRESET_DISABLED;
  pTimerCfg.DACSynchro = HRTIM_DACSYNC_NONE;
  pTimerCfg.PreloadEnable = HRTIM_PRELOAD_ENABLED;
  pTimerCfg.UpdateGating = HRTIM_UPDATEGATING_INDEPENDENT;
  pTimerCfg.BurstMode = HRTIM_TIMERBURSTMODE_MAINTAINCLOCK;
  pTimerCfg.RepetitionUpdate = HRTIM_UPDATEONREPETITION_DISABLED;
  pTimerCfg.PushPull = HRTIM_TIMPUSHPULLMODE_DISABLED;
  pTimerCfg.FaultEnable = HRTIM_TIMFAULTENABLE_NONE;
  pTimerCfg.FaultLock = HRTIM_TIMFAULTLOCK_READWRITE;
  pTimerCfg.DeadTimeInsertion = HRTIM_TIMDEADTIMEINSERTION_DISABLED;
  pTimerCfg.DelayedProtectionMode = HRTIM_TIMER_A_B_C_DELAYEDPROTECTION_DISABLED;
  pTimerCfg.UpdateTrigger = HRTIM_TIMUPDATETRIGGER_NONE;
  pTimerCfg.ResetTrigger = HRTIM_TIMRESETTRIGGER_EEV_1;
  pTimerCfg.ResetUpdate = HRTIM_TIMUPDATEONRESET_ENABLED;
  if (HAL_HRTIM_WaveformTimerConfig(&hhrtim, HRTIM_TIMERINDEX_TIMER_A, &pTimerCfg) != HAL_OK)
  {
    Error_Handler();
  }
  if (HAL_HRTIM_WaveformTimerConfig(&hhrtim, HRTIM_TIMERINDEX_TIMER_B, &pTimerCfg) != HAL_OK)
  {
    Error_Handler();
  }
  if (HAL_HRTIM_WaveformTimerConfig(&hhrtim, HRTIM_TIMERINDEX_TIMER_C, &pTimerCfg) != HAL_OK)
  {
    Error_Handler();
  }
  pTimerCfg.DelayedProtectionMode = HRTIM_TIMER_D_E_DELAYEDPROTECTION_DISABLED;
  if (HAL_HRTIM_WaveformTimerConfig(&hhrtim, HRTIM_TIMERINDEX_TIMER_D, &pTimerCfg) != HAL_OK)
  {
    Error_Handler();
  }
  pCompareCfg.CompareValue = (24000-1)/1000;
  if (HAL_HRTIM_WaveformCompareConfig(&hhrtim, HRTIM_TIMERINDEX_TIMER_A, HRTIM_COMPAREUNIT_1, &pCompareCfg) != HAL_OK)
  {
    Error_Handler();
  }
  pCompareCfg.AutoDelayedMode = HRTIM_AUTODELAYEDMODE_REGULAR;
  pCompareCfg.AutoDelayedTimeout = 0x0000;

  if (HAL_HRTIM_WaveformCompareConfig(&hhrtim, HRTIM_TIMERINDEX_TIMER_A, HRTIM_COMPAREUNIT_2, &pCompareCfg) != HAL_OK)
  {
    Error_Handler();
  }

  if (HAL_HRTIM_WaveformCompareConfig(&hhrtim, HRTIM_TIMERINDEX_TIMER_B, HRTIM_COMPAREUNIT_2, &pCompareCfg) != HAL_OK)
  {
    Error_Handler();
  }

  if (HAL_HRTIM_WaveformCompareConfig(&hhrtim, HRTIM_TIMERINDEX_TIMER_C, HRTIM_COMPAREUNIT_2, &pCompareCfg) != HAL_OK)
  {
    Error_Handler();
  }

  if (HAL_HRTIM_WaveformCompareConfig(&hhrtim, HRTIM_TIMERINDEX_TIMER_D, HRTIM_COMPAREUNIT_2, &pCompareCfg) != HAL_OK)
  {
    Error_Handler();
  }
  pOutputCfg.Polarity = HRTIM_OUTPUTPOLARITY_HIGH;
  pOutputCfg.SetSource = HRTIM_OUTPUTSET_EEV_1|HRTIM_OUTPUTSET_TIMPER;
  pOutputCfg.ResetSource = HRTIM_OUTPUTRESET_TIMCMP1;
  pOutputCfg.IdleMode = HRTIM_OUTPUTIDLEMODE_NONE;
  pOutputCfg.IdleLevel = HRTIM_OUTPUTIDLELEVEL_INACTIVE;
  pOutputCfg.FaultLevel = HRTIM_OUTPUTFAULTLEVEL_NONE;
  pOutputCfg.ChopperModeEnable = HRTIM_OUTPUTCHOPPERMODE_DISABLED;
  pOutputCfg.BurstModeEntryDelayed = HRTIM_OUTPUTBURSTMODEENTRY_REGULAR;
  if (HAL_HRTIM_WaveformOutputConfig(&hhrtim, HRTIM_TIMERINDEX_TIMER_A, HRTIM_OUTPUT_TA1, &pOutputCfg) != HAL_OK)
  {
    Error_Handler();
  }
  pOutputCfg.SetSource = HRTIM_OUTPUTSET_RESYNC|HRTIM_OUTPUTSET_TIMPER;
  if (HAL_HRTIM_WaveformOutputConfig(&hhrtim, HRTIM_TIMERINDEX_TIMER_B, HRTIM_OUTPUT_TB1, &pOutputCfg) != HAL_OK)
  {
    Error_Handler();
  }
  pOutputCfg.SetSource = HRTIM_OUTPUTSET_TIMPER|HRTIM_OUTPUTSET_RESYNC;
  if (HAL_HRTIM_WaveformOutputConfig(&hhrtim, HRTIM_TIMERINDEX_TIMER_C, HRTIM_OUTPUT_TC1, &pOutputCfg) != HAL_OK)
  {
    Error_Handler();
  }
  pOutputCfg.SetSource = HRTIM_OUTPUTSET_TIMPER;
  if (HAL_HRTIM_WaveformOutputConfig(&hhrtim, HRTIM_TIMERINDEX_TIMER_D, HRTIM_OUTPUT_TD1, &pOutputCfg) != HAL_OK)
  {
    Error_Handler();
  }
  pOutputCfg.SetSource = HRTIM_OUTPUTSET_TIMPER|HRTIM_OUTPUTSET_EEV_1;
  pOutputCfg.ResetSource = HRTIM_OUTPUTRESET_TIMCMP2;
  if (HAL_HRTIM_WaveformOutputConfig(&hhrtim, HRTIM_TIMERINDEX_TIMER_A, HRTIM_OUTPUT_TA2, &pOutputCfg) != HAL_OK)
  {
    Error_Handler();
  }
  pOutputCfg.SetSource = HRTIM_OUTPUTSET_RESYNC|HRTIM_OUTPUTSET_TIMPER;
  if (HAL_HRTIM_WaveformOutputConfig(&hhrtim, HRTIM_TIMERINDEX_TIMER_B, HRTIM_OUTPUT_TB2, &pOutputCfg) != HAL_OK)
  {
    Error_Handler();
  }
  pOutputCfg.SetSource = HRTIM_OUTPUTSET_TIMPER;
  if (HAL_HRTIM_WaveformOutputConfig(&hhrtim, HRTIM_TIMERINDEX_TIMER_C, HRTIM_OUTPUT_TC2, &pOutputCfg) != HAL_OK)
  {
    Error_Handler();
  }
  if (HAL_HRTIM_WaveformOutputConfig(&hhrtim, HRTIM_TIMERINDEX_TIMER_D, HRTIM_OUTPUT_TD2, &pOutputCfg) != HAL_OK)
  {
    Error_Handler();
  }
  pTimeBaseCfg.Period = 24000-1;
  if (HAL_HRTIM_TimeBaseConfig(&hhrtim, HRTIM_TIMERINDEX_TIMER_B, &pTimeBaseCfg) != HAL_OK)
  {
    Error_Handler();
  }
  if (HAL_HRTIM_WaveformCompareConfig(&hhrtim, HRTIM_TIMERINDEX_TIMER_B, HRTIM_COMPAREUNIT_1, &pCompareCfg) != HAL_OK)
  {
    Error_Handler();
  }
  if (HAL_HRTIM_TimeBaseConfig(&hhrtim, HRTIM_TIMERINDEX_TIMER_C, &pTimeBaseCfg) != HAL_OK)
  {
    Error_Handler();
  }
  pCompareCfg.CompareValue = (24000 -1)/1000;
  if (HAL_HRTIM_WaveformCompareConfig(&hhrtim, HRTIM_TIMERINDEX_TIMER_C, HRTIM_COMPAREUNIT_1, &pCompareCfg) != HAL_OK)
  {
    Error_Handler();
  }
  pTimeBaseCfg.Period = 24000 -1;
  if (HAL_HRTIM_TimeBaseConfig(&hhrtim, HRTIM_TIMERINDEX_TIMER_D, &pTimeBaseCfg) != HAL_OK)
  {
    Error_Handler();
  }
  pCompareCfg.CompareValue = (24000-1)/1000;
  if (HAL_HRTIM_WaveformCompareConfig(&hhrtim, HRTIM_TIMERINDEX_TIMER_D, HRTIM_COMPAREUNIT_1, &pCompareCfg) != HAL_OK)
  {
    Error_Handler();
  }
  HAL_HRTIM_MspPostInit(&hhrtim);

}

static void MX_I2C4_Init(void)
{

  hi2c4.Instance = I2C4;
  hi2c4.Init.Timing = 0x307075B1;
  hi2c4.Init.OwnAddress1 = 0;
  hi2c4.Init.AddressingMode = I2C_ADDRESSINGMODE_7BIT;
  hi2c4.Init.DualAddressMode = I2C_DUALADDRESS_DISABLE;
  hi2c4.Init.OwnAddress2 = 0;
  hi2c4.Init.OwnAddress2Masks = I2C_OA2_NOMASK;
  hi2c4.Init.GeneralCallMode = I2C_GENERALCALL_DISABLE;
  hi2c4.Init.NoStretchMode = I2C_NOSTRETCH_DISABLE;
  if (HAL_I2C_Init(&hi2c4) != HAL_OK)
  {
    Error_Handler();
  }

  /** Configure Analogue filter
  */
  if (HAL_I2CEx_ConfigAnalogFilter(&hi2c4, I2C_ANALOGFILTER_ENABLE) != HAL_OK)
  {
    Error_Handler();
  }

  /** Configure Digital filter
  */
  if (HAL_I2CEx_ConfigDigitalFilter(&hi2c4, 0) != HAL_OK)
  {
    Error_Handler();
  }

}

static void MX_LPTIM1_Init(void)
{

  hlptim1.Instance = LPTIM1;
  hlptim1.Init.Clock.Source = LPTIM_CLOCKSOURCE_APBCLOCK_LPOSC;
  hlptim1.Init.Clock.Prescaler = LPTIM_PRESCALER_DIV1;
  hlptim1.Init.Trigger.Source = LPTIM_TRIGSOURCE_SOFTWARE;
  hlptim1.Init.OutputPolarity = LPTIM_OUTPUTPOLARITY_HIGH;
  hlptim1.Init.UpdateMode = LPTIM_UPDATE_IMMEDIATE;
  hlptim1.Init.CounterSource = LPTIM_COUNTERSOURCE_INTERNAL;
  hlptim1.Init.Input1Source = LPTIM_INPUT1SOURCE_GPIO;
  hlptim1.Init.Input2Source = LPTIM_INPUT2SOURCE_GPIO;
  if (HAL_LPTIM_Init(&hlptim1) != HAL_OK)
  {
    Error_Handler();
  }

}

static void MX_LPTIM2_Init(void)
{

  hlptim2.Instance = LPTIM2;
  hlptim2.Init.Clock.Source = LPTIM_CLOCKSOURCE_APBCLOCK_LPOSC;
  hlptim2.Init.Clock.Prescaler = LPTIM_PRESCALER_DIV1;
  hlptim2.Init.Trigger.Source = LPTIM_TRIGSOURCE_SOFTWARE;
  hlptim2.Init.OutputPolarity = LPTIM_OUTPUTPOLARITY_HIGH;
  hlptim2.Init.UpdateMode = LPTIM_UPDATE_IMMEDIATE;
  hlptim2.Init.CounterSource = LPTIM_COUNTERSOURCE_INTERNAL;
  hlptim2.Init.Input1Source = LPTIM_INPUT1SOURCE_GPIO;
  hlptim2.Init.Input2Source = LPTIM_INPUT2SOURCE_GPIO;
  if (HAL_LPTIM_Init(&hlptim2) != HAL_OK)
  {
    Error_Handler();
  }

}

static void MX_LPTIM3_Init(void)
{

  hlptim3.Instance = LPTIM3;
  hlptim3.Init.Clock.Source = LPTIM_CLOCKSOURCE_APBCLOCK_LPOSC;
  hlptim3.Init.Clock.Prescaler = LPTIM_PRESCALER_DIV1;
  hlptim3.Init.Trigger.Source = LPTIM_TRIGSOURCE_SOFTWARE;
  hlptim3.Init.OutputPolarity = LPTIM_OUTPUTPOLARITY_HIGH;
  hlptim3.Init.UpdateMode = LPTIM_UPDATE_IMMEDIATE;
  hlptim3.Init.CounterSource = LPTIM_COUNTERSOURCE_INTERNAL;
  hlptim3.Init.Input1Source = LPTIM_INPUT1SOURCE_GPIO;
  if (HAL_LPTIM_Init(&hlptim3) != HAL_OK)
  {
    Error_Handler();
  }

}

static void MX_SPI2_Init(void)
{

  /* SPI2 parameter configuration*/
  hspi2.Instance = SPI2;
  hspi2.Init.Mode = SPI_MODE_MASTER;
  hspi2.Init.Direction = SPI_DIRECTION_2LINES;
  hspi2.Init.DataSize = SPI_DATASIZE_8BIT;
  hspi2.Init.CLKPolarity = SPI_POLARITY_LOW;
  hspi2.Init.CLKPhase = SPI_PHASE_1EDGE;
  hspi2.Init.NSS = SPI_NSS_HARD_OUTPUT;
  hspi2.Init.BaudRatePrescaler = SPI_BAUDRATEPRESCALER_32;
  hspi2.Init.FirstBit = SPI_FIRSTBIT_MSB;
  hspi2.Init.TIMode = SPI_TIMODE_DISABLE;
  hspi2.Init.CRCCalculation = SPI_CRCCALCULATION_DISABLE;
  hspi2.Init.CRCPolynomial = 0x0;
  hspi2.Init.NSSPMode = SPI_NSS_PULSE_ENABLE;
  hspi2.Init.NSSPolarity = SPI_NSS_POLARITY_LOW;
  hspi2.Init.FifoThreshold = SPI_FIFO_THRESHOLD_01DATA;
  hspi2.Init.TxCRCInitializationPattern = SPI_CRC_INITIALIZATION_ALL_ZERO_PATTERN;
  hspi2.Init.RxCRCInitializationPattern = SPI_CRC_INITIALIZATION_ALL_ZERO_PATTERN;
  hspi2.Init.MasterSSIdleness = SPI_MASTER_SS_IDLENESS_00CYCLE;
  hspi2.Init.MasterInterDataIdleness = SPI_MASTER_INTERDATA_IDLENESS_00CYCLE;
  hspi2.Init.MasterReceiverAutoSusp = SPI_MASTER_RX_AUTOSUSP_DISABLE;
  hspi2.Init.MasterKeepIOState = SPI_MASTER_KEEP_IO_STATE_DISABLE;
  hspi2.Init.IOSwap = SPI_IO_SWAP_DISABLE;
  if (HAL_SPI_Init(&hspi2) != HAL_OK)
  {
    Error_Handler();
  }

}

static void MX_SPI6_Init(void)
{

  /* SPI6 parameter configuration*/
  hspi6.Instance = SPI6;
  hspi6.Init.Mode = SPI_MODE_SLAVE;
  hspi6.Init.Direction = SPI_DIRECTION_2LINES;
  hspi6.Init.DataSize = SPI_DATASIZE_8BIT;
  hspi6.Init.CLKPolarity = SPI_POLARITY_LOW;
  hspi6.Init.CLKPhase = SPI_PHASE_1EDGE;
  hspi6.Init.NSS = SPI_NSS_HARD_INPUT;
  hspi6.Init.FirstBit = SPI_FIRSTBIT_MSB;
  hspi6.Init.TIMode = SPI_TIMODE_DISABLE;
  hspi6.Init.CRCCalculation = SPI_CRCCALCULATION_DISABLE;
  hspi6.Init.CRCPolynomial = 0x0;
  hspi6.Init.NSSPMode = SPI_NSS_PULSE_DISABLE;
  hspi6.Init.NSSPolarity = SPI_NSS_POLARITY_LOW;
  hspi6.Init.FifoThreshold = SPI_FIFO_THRESHOLD_01DATA;
  hspi6.Init.TxCRCInitializationPattern = SPI_CRC_INITIALIZATION_ALL_ZERO_PATTERN;
  hspi6.Init.RxCRCInitializationPattern = SPI_CRC_INITIALIZATION_ALL_ZERO_PATTERN;
  hspi6.Init.MasterSSIdleness = SPI_MASTER_SS_IDLENESS_00CYCLE;
  hspi6.Init.MasterInterDataIdleness = SPI_MASTER_INTERDATA_IDLENESS_00CYCLE;
  hspi6.Init.MasterReceiverAutoSusp = SPI_MASTER_RX_AUTOSUSP_DISABLE;
  hspi6.Init.MasterKeepIOState = SPI_MASTER_KEEP_IO_STATE_DISABLE;
  hspi6.Init.IOSwap = SPI_IO_SWAP_DISABLE;
  if (HAL_SPI_Init(&hspi6) != HAL_OK)
  {
    Error_Handler();
  }
  /* USER CODE BEGIN SPI6_Init 2 */
//  SPI6->IER |= (SPI_IER_TXPIE|SPI_IER_RXPIE);

  /* USER CODE END SPI6_Init 2 */

}

static void MX_TIM1_Init(void)
{

  TIM_ClockConfigTypeDef sClockSourceConfig = {0};
  TIM_MasterConfigTypeDef sMasterConfig = {0};
  TIM_OC_InitTypeDef sConfigOC = {0};
  TIM_BreakDeadTimeConfigTypeDef sBreakDeadTimeConfig = {0};

  htim1.Instance = TIM1;
  htim1.Init.Prescaler = 0;
  htim1.Init.CounterMode = TIM_COUNTERMODE_UP;
  htim1.Init.Period = 24000-1;
  htim1.Init.ClockDivision = TIM_CLOCKDIVISION_DIV1;
  htim1.Init.RepetitionCounter = 0;
  htim1.Init.AutoReloadPreload = TIM_AUTORELOAD_PRELOAD_ENABLE;
  if (HAL_TIM_Base_Init(&htim1) != HAL_OK)
  {
    Error_Handler();
  }
  sClockSourceConfig.ClockSource = TIM_CLOCKSOURCE_INTERNAL;
  if (HAL_TIM_ConfigClockSource(&htim1, &sClockSourceConfig) != HAL_OK)
  {
    Error_Handler();
  }
  if (HAL_TIM_PWM_Init(&htim1) != HAL_OK)
  {
    Error_Handler();
  }
  sMasterConfig.MasterOutputTrigger = TIM_TRGO_UPDATE;
  sMasterConfig.MasterOutputTrigger2 = TIM_TRGO2_RESET;
  sMasterConfig.MasterSlaveMode = TIM_MASTERSLAVEMODE_ENABLE;
  if (HAL_TIMEx_MasterConfigSynchronization(&htim1, &sMasterConfig) != HAL_OK)
  {
    Error_Handler();
  }
  sConfigOC.OCMode = TIM_OCMODE_PWM1;
  sConfigOC.Pulse = (24000-1)/1000;
  sConfigOC.OCPolarity = TIM_OCPOLARITY_HIGH;
  sConfigOC.OCNPolarity = TIM_OCNPOLARITY_HIGH;
  sConfigOC.OCFastMode = TIM_OCFAST_DISABLE;
  sConfigOC.OCIdleState = TIM_OCIDLESTATE_RESET;
  sConfigOC.OCNIdleState = TIM_OCNIDLESTATE_RESET;
  if (HAL_TIM_PWM_ConfigChannel(&htim1, &sConfigOC, TIM_CHANNEL_1) != HAL_OK)
  {
    Error_Handler();
  }
  if (HAL_TIM_PWM_ConfigChannel(&htim1, &sConfigOC, TIM_CHANNEL_2) != HAL_OK)
  {
    Error_Handler();
  }
  if (HAL_TIM_PWM_ConfigChannel(&htim1, &sConfigOC, TIM_CHANNEL_3) != HAL_OK)
  {
    Error_Handler();
  }
  if (HAL_TIM_PWM_ConfigChannel(&htim1, &sConfigOC, TIM_CHANNEL_4) != HAL_OK)
  {
    Error_Handler();
  }
  sBreakDeadTimeConfig.OffStateRunMode = TIM_OSSR_DISABLE;
  sBreakDeadTimeConfig.OffStateIDLEMode = TIM_OSSI_DISABLE;
  sBreakDeadTimeConfig.LockLevel = TIM_LOCKLEVEL_OFF;
  sBreakDeadTimeConfig.DeadTime = 0;
  sBreakDeadTimeConfig.BreakState = TIM_BREAK_DISABLE;
  sBreakDeadTimeConfig.BreakPolarity = TIM_BREAKPOLARITY_HIGH;
  sBreakDeadTimeConfig.BreakFilter = 0;
  sBreakDeadTimeConfig.Break2State = TIM_BREAK2_DISABLE;
  sBreakDeadTimeConfig.Break2Polarity = TIM_BREAK2POLARITY_HIGH;
  sBreakDeadTimeConfig.Break2Filter = 0;
  sBreakDeadTimeConfig.AutomaticOutput = TIM_AUTOMATICOUTPUT_DISABLE;
  if (HAL_TIMEx_ConfigBreakDeadTime(&htim1, &sBreakDeadTimeConfig) != HAL_OK)
  {
    Error_Handler();
  }
  HAL_TIM_MspPostInit(&htim1);

}

static void MX_TIM2_Init(void)
{

  TIM_MasterConfigTypeDef sMasterConfig = {0};
  TIM_OC_InitTypeDef sConfigOC = {0};

  htim2.Instance = TIM2;
  htim2.Init.Prescaler = 0;
  htim2.Init.CounterMode = TIM_COUNTERMODE_UP;
  htim2.Init.Period = 24000 -1;
  htim2.Init.ClockDivision = TIM_CLOCKDIVISION_DIV1;
  htim2.Init.AutoReloadPreload = TIM_AUTORELOAD_PRELOAD_DISABLE;
  if (HAL_TIM_PWM_Init(&htim2) != HAL_OK)
  {
    Error_Handler();
  }
  sMasterConfig.MasterOutputTrigger = TIM_TRGO_RESET;
  sMasterConfig.MasterSlaveMode = TIM_MASTERSLAVEMODE_DISABLE;
  if (HAL_TIMEx_MasterConfigSynchronization(&htim2, &sMasterConfig) != HAL_OK)
  {
    Error_Handler();
  }
  sConfigOC.OCMode = TIM_OCMODE_PWM1;
  sConfigOC.Pulse = (24000 -1)/1000;
  sConfigOC.OCPolarity = TIM_OCPOLARITY_HIGH;
  sConfigOC.OCFastMode = TIM_OCFAST_DISABLE;
  if (HAL_TIM_PWM_ConfigChannel(&htim2, &sConfigOC, TIM_CHANNEL_1) != HAL_OK)
  {
    Error_Handler();
  }
  sConfigOC.Pulse = (24000-1)/1000;
  if (HAL_TIM_PWM_ConfigChannel(&htim2, &sConfigOC, TIM_CHANNEL_4) != HAL_OK)
  {
    Error_Handler();
  }
  HAL_TIM_MspPostInit(&htim2);

}

static void MX_TIM4_Init(void)
{

  TIM_ClockConfigTypeDef sClockSourceConfig = {0};
  TIM_SlaveConfigTypeDef sSlaveConfig = {0};
  TIM_MasterConfigTypeDef sMasterConfig = {0};
  TIM_OC_InitTypeDef sConfigOC = {0};

  htim4.Instance = TIM4;
  htim4.Init.Prescaler = 0;
  htim4.Init.CounterMode = TIM_COUNTERMODE_UP;
  htim4.Init.Period = 24000-1;
  htim4.Init.ClockDivision = TIM_CLOCKDIVISION_DIV1;
  htim4.Init.AutoReloadPreload = TIM_AUTORELOAD_PRELOAD_DISABLE;
  if (HAL_TIM_Base_Init(&htim4) != HAL_OK)
  {
    Error_Handler();
  }
  sClockSourceConfig.ClockSource = TIM_CLOCKSOURCE_INTERNAL;
  if (HAL_TIM_ConfigClockSource(&htim4, &sClockSourceConfig) != HAL_OK)
  {
    Error_Handler();
  }
  if (HAL_TIM_PWM_Init(&htim4) != HAL_OK)
  {
    Error_Handler();
  }
  sSlaveConfig.SlaveMode = TIM_SLAVEMODE_RESET;
  sSlaveConfig.InputTrigger = TIM_TS_ITR0;
  if (HAL_TIM_SlaveConfigSynchro(&htim4, &sSlaveConfig) != HAL_OK)
  {
    Error_Handler();
  }
  sMasterConfig.MasterOutputTrigger = TIM_TRGO_UPDATE;
  sMasterConfig.MasterSlaveMode = TIM_MASTERSLAVEMODE_DISABLE;
  if (HAL_TIMEx_MasterConfigSynchronization(&htim4, &sMasterConfig) != HAL_OK)
  {
    Error_Handler();
  }
  sConfigOC.OCMode = TIM_OCMODE_PWM1;
  sConfigOC.Pulse = (24000 -1)/1000;
  sConfigOC.OCPolarity = TIM_OCPOLARITY_HIGH;
  sConfigOC.OCFastMode = TIM_OCFAST_DISABLE;
  if (HAL_TIM_PWM_ConfigChannel(&htim4, &sConfigOC, TIM_CHANNEL_1) != HAL_OK)
  {
    Error_Handler();
  }
  sConfigOC.Pulse = (24000-1)/1000;
  if (HAL_TIM_PWM_ConfigChannel(&htim4, &sConfigOC, TIM_CHANNEL_2) != HAL_OK)
  {
    Error_Handler();
  }
  if (HAL_TIM_PWM_ConfigChannel(&htim4, &sConfigOC, TIM_CHANNEL_3) != HAL_OK)
  {
    Error_Handler();
  }
  if (HAL_TIM_PWM_ConfigChannel(&htim4, &sConfigOC, TIM_CHANNEL_4) != HAL_OK)
  {
    Error_Handler();
  }
  HAL_TIM_MspPostInit(&htim4);

}

static void MX_TIM5_Init(void)
{

  TIM_SlaveConfigTypeDef sSlaveConfig = {0};
  TIM_MasterConfigTypeDef sMasterConfig = {0};
  TIM_OC_InitTypeDef sConfigOC = {0};

  htim5.Instance = TIM5;
  htim5.Init.Prescaler = 0;
  htim5.Init.CounterMode = TIM_COUNTERMODE_UP;
  htim5.Init.Period = (24000-1);
  htim5.Init.ClockDivision = TIM_CLOCKDIVISION_DIV1;
  htim5.Init.AutoReloadPreload = TIM_AUTORELOAD_PRELOAD_ENABLE;
  if (HAL_TIM_Base_Init(&htim5) != HAL_OK)
  {
    Error_Handler();
  }
  if (HAL_TIM_PWM_Init(&htim5) != HAL_OK)
  {
    Error_Handler();
  }
  sSlaveConfig.SlaveMode = TIM_SLAVEMODE_RESET;
  sSlaveConfig.InputTrigger = TIM_TS_ITR0;
  if (HAL_TIM_SlaveConfigSynchro(&htim5, &sSlaveConfig) != HAL_OK)
  {
    Error_Handler();
  }
  sMasterConfig.MasterOutputTrigger = TIM_TRGO_RESET;
  sMasterConfig.MasterSlaveMode = TIM_MASTERSLAVEMODE_DISABLE;
  if (HAL_TIMEx_MasterConfigSynchronization(&htim5, &sMasterConfig) != HAL_OK)
  {
    Error_Handler();
  }
  sConfigOC.OCMode = TIM_OCMODE_PWM1;
  sConfigOC.Pulse = (24000-1)/1000;
  sConfigOC.OCPolarity = TIM_OCPOLARITY_HIGH;
  sConfigOC.OCFastMode = TIM_OCFAST_DISABLE;
  if (HAL_TIM_PWM_ConfigChannel(&htim5, &sConfigOC, TIM_CHANNEL_2) != HAL_OK)
  {
    Error_Handler();
  }
  if (HAL_TIM_PWM_ConfigChannel(&htim5, &sConfigOC, TIM_CHANNEL_3) != HAL_OK)
  {
    Error_Handler();
  }
  HAL_TIM_MspPostInit(&htim5);

}

static void MX_TIM8_Init(void)
{

  TIM_SlaveConfigTypeDef sSlaveConfig = {0};
  TIM_MasterConfigTypeDef sMasterConfig = {0};
  TIM_OC_InitTypeDef sConfigOC = {0};
  TIM_BreakDeadTimeConfigTypeDef sBreakDeadTimeConfig = {0};

  htim8.Instance = TIM8;
  htim8.Init.Prescaler = 0;
  htim8.Init.CounterMode = TIM_COUNTERMODE_UP;
  htim8.Init.Period = 24000 -1;
  htim8.Init.ClockDivision = TIM_CLOCKDIVISION_DIV1;
  htim8.Init.RepetitionCounter = 0;
  htim8.Init.AutoReloadPreload = TIM_AUTORELOAD_PRELOAD_ENABLE;
  if (HAL_TIM_Base_Init(&htim8) != HAL_OK)
  {
    Error_Handler();
  }
  if (HAL_TIM_PWM_Init(&htim8) != HAL_OK)
  {
    Error_Handler();
  }
  sSlaveConfig.SlaveMode = TIM_SLAVEMODE_RESET;
  sSlaveConfig.InputTrigger = TIM_TS_ITR0;
  if (HAL_TIM_SlaveConfigSynchro(&htim8, &sSlaveConfig) != HAL_OK)
  {
    Error_Handler();
  }
  sMasterConfig.MasterOutputTrigger = TIM_TRGO_RESET;
  sMasterConfig.MasterOutputTrigger2 = TIM_TRGO2_RESET;
  sMasterConfig.MasterSlaveMode = TIM_MASTERSLAVEMODE_DISABLE;
  if (HAL_TIMEx_MasterConfigSynchronization(&htim8, &sMasterConfig) != HAL_OK)
  {
    Error_Handler();
  }
  sConfigOC.OCMode = TIM_OCMODE_PWM1;
  sConfigOC.Pulse = (24000-1)/1000;
  sConfigOC.OCPolarity = TIM_OCPOLARITY_HIGH;
  sConfigOC.OCFastMode = TIM_OCFAST_DISABLE;
  sConfigOC.OCIdleState = TIM_OCIDLESTATE_RESET;
  sConfigOC.OCNIdleState = TIM_OCNIDLESTATE_RESET;
  if (HAL_TIM_PWM_ConfigChannel(&htim8, &sConfigOC, TIM_CHANNEL_4) != HAL_OK)
  {
    Error_Handler();
  }
  sBreakDeadTimeConfig.OffStateRunMode = TIM_OSSR_DISABLE;
  sBreakDeadTimeConfig.OffStateIDLEMode = TIM_OSSI_DISABLE;
  sBreakDeadTimeConfig.LockLevel = TIM_LOCKLEVEL_OFF;
  sBreakDeadTimeConfig.DeadTime = 0;
  sBreakDeadTimeConfig.BreakState = TIM_BREAK_DISABLE;
  sBreakDeadTimeConfig.BreakPolarity = TIM_BREAKPOLARITY_HIGH;
  sBreakDeadTimeConfig.BreakFilter = 0;
  sBreakDeadTimeConfig.Break2State = TIM_BREAK2_DISABLE;
  sBreakDeadTimeConfig.Break2Polarity = TIM_BREAK2POLARITY_HIGH;
  sBreakDeadTimeConfig.Break2Filter = 0;
  sBreakDeadTimeConfig.AutomaticOutput = TIM_AUTOMATICOUTPUT_DISABLE;
  if (HAL_TIMEx_ConfigBreakDeadTime(&htim8, &sBreakDeadTimeConfig) != HAL_OK)
  {
    Error_Handler();
  }
  HAL_TIM_MspPostInit(&htim8);

}

static void MX_TIM12_Init(void)
{

  TIM_SlaveConfigTypeDef sSlaveConfig = {0};
  TIM_MasterConfigTypeDef sMasterConfig = {0};
  TIM_OC_InitTypeDef sConfigOC = {0};

  htim12.Instance = TIM12;
  htim12.Init.Prescaler = 0;
  htim12.Init.CounterMode = TIM_COUNTERMODE_UP;
  htim12.Init.Period = 24000-1;
  htim12.Init.ClockDivision = TIM_CLOCKDIVISION_DIV1;
  htim12.Init.AutoReloadPreload = TIM_AUTORELOAD_PRELOAD_ENABLE;
  if (HAL_TIM_Base_Init(&htim12) != HAL_OK)
  {
    Error_Handler();
  }
  if (HAL_TIM_PWM_Init(&htim12) != HAL_OK)
  {
    Error_Handler();
  }
  sSlaveConfig.SlaveMode = TIM_SLAVEMODE_RESET;
  sSlaveConfig.InputTrigger = TIM_TS_ITR0;
  if (HAL_TIM_SlaveConfigSynchro(&htim12, &sSlaveConfig) != HAL_OK)
  {
    Error_Handler();
  }
  sMasterConfig.MasterOutputTrigger = TIM_TRGO_RESET;
  sMasterConfig.MasterSlaveMode = TIM_MASTERSLAVEMODE_DISABLE;
  if (HAL_TIMEx_MasterConfigSynchronization(&htim12, &sMasterConfig) != HAL_OK)
  {
    Error_Handler();
  }
  sConfigOC.OCMode = TIM_OCMODE_PWM1;
  sConfigOC.Pulse = (24000-1)/1000;
  sConfigOC.OCPolarity = TIM_OCPOLARITY_HIGH;
  sConfigOC.OCFastMode = TIM_OCFAST_DISABLE;
  if (HAL_TIM_PWM_ConfigChannel(&htim12, &sConfigOC, TIM_CHANNEL_2) != HAL_OK)
  {
    Error_Handler();
  }
  HAL_TIM_MspPostInit(&htim12);

}

static void MX_TIM13_Init(void)
{

  TIM_OC_InitTypeDef sConfigOC = {0};

  htim13.Instance = TIM13;
  htim13.Init.Prescaler = 0;
  htim13.Init.CounterMode = TIM_COUNTERMODE_UP;
  htim13.Init.Period = 24000-1;
  htim13.Init.ClockDivision = TIM_CLOCKDIVISION_DIV1;
  htim13.Init.AutoReloadPreload = TIM_AUTORELOAD_PRELOAD_DISABLE;
  if (HAL_TIM_Base_Init(&htim13) != HAL_OK)
  {
    Error_Handler();
  }
  if (HAL_TIM_PWM_Init(&htim13) != HAL_OK)
  {
    Error_Handler();
  }
  sConfigOC.OCMode = TIM_OCMODE_PWM1;
  sConfigOC.Pulse = (24000-1)/1000;
  sConfigOC.OCPolarity = TIM_OCPOLARITY_HIGH;
  sConfigOC.OCFastMode = TIM_OCFAST_DISABLE;
  if (HAL_TIM_PWM_ConfigChannel(&htim13, &sConfigOC, TIM_CHANNEL_1) != HAL_OK)
  {
    Error_Handler();
  }
  HAL_TIM_MspPostInit(&htim13);

}

static void MX_TIM14_Init(void)
{

  TIM_OC_InitTypeDef sConfigOC = {0};

  htim14.Instance = TIM14;
  htim14.Init.Prescaler = 0;
  htim14.Init.CounterMode = TIM_COUNTERMODE_UP;
  htim14.Init.Period = 24000-1;
  htim14.Init.ClockDivision = TIM_CLOCKDIVISION_DIV1;
  htim14.Init.AutoReloadPreload = TIM_AUTORELOAD_PRELOAD_DISABLE;
  if (HAL_TIM_Base_Init(&htim14) != HAL_OK)
  {
    Error_Handler();
  }
  if (HAL_TIM_PWM_Init(&htim14) != HAL_OK)
  {
    Error_Handler();
  }
  sConfigOC.OCMode = TIM_OCMODE_PWM1;
  sConfigOC.Pulse = (24000-1)/1000;
  sConfigOC.OCPolarity = TIM_OCPOLARITY_HIGH;
  sConfigOC.OCFastMode = TIM_OCFAST_DISABLE;
  if (HAL_TIM_PWM_ConfigChannel(&htim14, &sConfigOC, TIM_CHANNEL_1) != HAL_OK)
  {
    Error_Handler();
  }
  HAL_TIM_MspPostInit(&htim14);

}

static void MX_TIM15_Init(void)
{

  TIM_SlaveConfigTypeDef sSlaveConfig = {0};
  TIM_MasterConfigTypeDef sMasterConfig = {0};
  TIM_OC_InitTypeDef sConfigOC = {0};
  TIM_BreakDeadTimeConfigTypeDef sBreakDeadTimeConfig = {0};

  htim15.Instance = TIM15;
  htim15.Init.Prescaler = 0;
  htim15.Init.CounterMode = TIM_COUNTERMODE_UP;
  htim15.Init.Period = 24000-1;
  htim15.Init.ClockDivision = TIM_CLOCKDIVISION_DIV1;
  htim15.Init.RepetitionCounter = 0;
  htim15.Init.AutoReloadPreload = TIM_AUTORELOAD_PRELOAD_DISABLE;
  if (HAL_TIM_Base_Init(&htim15) != HAL_OK)
  {
    Error_Handler();
  }
  if (HAL_TIM_PWM_Init(&htim15) != HAL_OK)
  {
    Error_Handler();
  }
  sSlaveConfig.SlaveMode = TIM_SLAVEMODE_RESET;
  sSlaveConfig.InputTrigger = TIM_TS_ITR0;
  if (HAL_TIM_SlaveConfigSynchro(&htim15, &sSlaveConfig) != HAL_OK)
  {
    Error_Handler();
  }
  sMasterConfig.MasterOutputTrigger = TIM_TRGO_RESET;
  sMasterConfig.MasterSlaveMode = TIM_MASTERSLAVEMODE_DISABLE;
  if (HAL_TIMEx_MasterConfigSynchronization(&htim15, &sMasterConfig) != HAL_OK)
  {
    Error_Handler();
  }
  sConfigOC.OCMode = TIM_OCMODE_PWM1;
  sConfigOC.Pulse = (24000-1)/1000;
  sConfigOC.OCPolarity = TIM_OCPOLARITY_HIGH;
  sConfigOC.OCNPolarity = TIM_OCNPOLARITY_HIGH;
  sConfigOC.OCFastMode = TIM_OCFAST_DISABLE;
  sConfigOC.OCIdleState = TIM_OCIDLESTATE_RESET;
  sConfigOC.OCNIdleState = TIM_OCNIDLESTATE_RESET;
  if (HAL_TIM_PWM_ConfigChannel(&htim15, &sConfigOC, TIM_CHANNEL_1) != HAL_OK)
  {
    Error_Handler();
  }
  if (HAL_TIM_PWM_ConfigChannel(&htim15, &sConfigOC, TIM_CHANNEL_2) != HAL_OK)
  {
    Error_Handler();
  }
  sBreakDeadTimeConfig.OffStateRunMode = TIM_OSSR_DISABLE;
  sBreakDeadTimeConfig.OffStateIDLEMode = TIM_OSSI_DISABLE;
  sBreakDeadTimeConfig.LockLevel = TIM_LOCKLEVEL_OFF;
  sBreakDeadTimeConfig.DeadTime = 0;
  sBreakDeadTimeConfig.BreakState = TIM_BREAK_DISABLE;
  sBreakDeadTimeConfig.BreakPolarity = TIM_BREAKPOLARITY_HIGH;
  sBreakDeadTimeConfig.BreakFilter = 0;
  sBreakDeadTimeConfig.AutomaticOutput = TIM_AUTOMATICOUTPUT_DISABLE;
  if (HAL_TIMEx_ConfigBreakDeadTime(&htim15, &sBreakDeadTimeConfig) != HAL_OK)
  {
    Error_Handler();
  }
  HAL_TIM_MspPostInit(&htim15);

}

static void MX_TIM16_Init(void)
{

  TIM_OC_InitTypeDef sConfigOC = {0};
  TIM_BreakDeadTimeConfigTypeDef sBreakDeadTimeConfig = {0};

  htim16.Instance = TIM16;
  htim16.Init.Prescaler = 0;
  htim16.Init.CounterMode = TIM_COUNTERMODE_UP;
  htim16.Init.Period = 24000-1;
  htim16.Init.ClockDivision = TIM_CLOCKDIVISION_DIV1;
  htim16.Init.RepetitionCounter = 0;
  htim16.Init.AutoReloadPreload = TIM_AUTORELOAD_PRELOAD_DISABLE;
  if (HAL_TIM_Base_Init(&htim16) != HAL_OK)
  {
    Error_Handler();
  }
  if (HAL_TIM_PWM_Init(&htim16) != HAL_OK)
  {
    Error_Handler();
  }
  sConfigOC.OCMode = TIM_OCMODE_PWM1;
  sConfigOC.Pulse = (24000-1)/1000;
  sConfigOC.OCPolarity = TIM_OCPOLARITY_HIGH;
  sConfigOC.OCNPolarity = TIM_OCNPOLARITY_HIGH;
  sConfigOC.OCFastMode = TIM_OCFAST_DISABLE;
  sConfigOC.OCIdleState = TIM_OCIDLESTATE_RESET;
  sConfigOC.OCNIdleState = TIM_OCNIDLESTATE_RESET;
  if (HAL_TIM_PWM_ConfigChannel(&htim16, &sConfigOC, TIM_CHANNEL_1) != HAL_OK)
  {
    Error_Handler();
  }
  sBreakDeadTimeConfig.OffStateRunMode = TIM_OSSR_DISABLE;
  sBreakDeadTimeConfig.OffStateIDLEMode = TIM_OSSI_DISABLE;
  sBreakDeadTimeConfig.LockLevel = TIM_LOCKLEVEL_OFF;
  sBreakDeadTimeConfig.DeadTime = 0;
  sBreakDeadTimeConfig.BreakState = TIM_BREAK_DISABLE;
  sBreakDeadTimeConfig.BreakPolarity = TIM_BREAKPOLARITY_HIGH;
  sBreakDeadTimeConfig.BreakFilter = 0;
  sBreakDeadTimeConfig.AutomaticOutput = TIM_AUTOMATICOUTPUT_DISABLE;
  if (HAL_TIMEx_ConfigBreakDeadTime(&htim16, &sBreakDeadTimeConfig) != HAL_OK)
  {
    Error_Handler();
  }
  HAL_TIM_MspPostInit(&htim16);

}

static void MX_UART4_Init(void)
{

  LL_USART_InitTypeDef UART_InitStruct = {0};

  LL_GPIO_InitTypeDef GPIO_InitStruct = {0};
  RCC_PeriphCLKInitTypeDef PeriphClkInitStruct = {0};

  /** Initializes the peripherals clock
  */
  PeriphClkInitStruct.PeriphClockSelection = RCC_PERIPHCLK_UART4;
  PeriphClkInitStruct.Usart234578ClockSelection = RCC_USART234578CLKSOURCE_D2PCLK1;
  if (HAL_RCCEx_PeriphCLKConfig(&PeriphClkInitStruct) != HAL_OK)
  {
    Error_Handler();
  }

  /* Peripheral clock enable */
  LL_APB1_GRP1_EnableClock(LL_APB1_GRP1_PERIPH_UART4);

  LL_AHB4_GRP1_EnableClock(LL_AHB4_GRP1_PERIPH_GPIOC);
  /**UART4 GPIO Configuration
  PC10   ------> UART4_TX
  PC11   ------> UART4_RX
  */
  GPIO_InitStruct.Pin = LL_GPIO_PIN_10|LL_GPIO_PIN_11;
  GPIO_InitStruct.Mode = LL_GPIO_MODE_ALTERNATE;
  GPIO_InitStruct.Speed = LL_GPIO_SPEED_FREQ_LOW;
  GPIO_InitStruct.OutputType = LL_GPIO_OUTPUT_PUSHPULL;
  GPIO_InitStruct.Pull = LL_GPIO_PULL_NO;
  GPIO_InitStruct.Alternate = LL_GPIO_AF_8;
  LL_GPIO_Init(GPIOC, &GPIO_InitStruct);

  /* UART4 interrupt Init */
  NVIC_SetPriority(UART4_IRQn, NVIC_EncodePriority(NVIC_GetPriorityGrouping(),2, 0));
  NVIC_EnableIRQ(UART4_IRQn);

  UART_InitStruct.PrescalerValue = LL_USART_PRESCALER_DIV1;
  UART_InitStruct.BaudRate = 115200;
  UART_InitStruct.DataWidth = LL_USART_DATAWIDTH_8B;
  UART_InitStruct.StopBits = LL_USART_STOPBITS_1;
  UART_InitStruct.Parity = LL_USART_PARITY_NONE;
  UART_InitStruct.TransferDirection = LL_USART_DIRECTION_TX_RX;
  UART_InitStruct.HardwareFlowControl = LL_USART_HWCONTROL_NONE;
  UART_InitStruct.OverSampling = LL_USART_OVERSAMPLING_16;
  LL_USART_Init(UART4, &UART_InitStruct);
  LL_USART_DisableFIFO(UART4);
  LL_USART_SetTXFIFOThreshold(UART4, LL_USART_FIFOTHRESHOLD_1_8);
  LL_USART_SetRXFIFOThreshold(UART4, LL_USART_FIFOTHRESHOLD_1_8);
  LL_USART_ConfigAsyncMode(UART4);

  LL_USART_Enable(UART4);

  /* Polling UART4 initialisation */
  while((!(LL_USART_IsActiveFlag_TEACK(UART4))) || (!(LL_USART_IsActiveFlag_REACK(UART4))))
  {
  }
  /* USER CODE BEGIN UART4_Init 2 */

  /* CR1 register settings:
   * TE = Transmitter enable
   * RE = Receiver enable
   * UE = USART enable
   * RXNEIE = Receive data register not empty interrupt enable  */
  UART4->CR1 |= (USART_CR1_TE|USART_CR1_RXNEIE|USART_CR1_RE|USART_CR1_UE);

  /* USER CODE END UART4_Init 2 */

}

static void MX_GPIO_Init(void)
{
  GPIO_InitTypeDef GPIO_InitStruct = {0};

  /* GPIO Ports Clock Enable */
  __HAL_RCC_GPIOE_CLK_ENABLE();
  __HAL_RCC_GPIOC_CLK_ENABLE();
  __HAL_RCC_GPIOH_CLK_ENABLE();
  __HAL_RCC_GPIOA_CLK_ENABLE();
  __HAL_RCC_GPIOB_CLK_ENABLE();
  __HAL_RCC_GPIOD_CLK_ENABLE();

  /*Configure GPIO pin Output Level */
  HAL_GPIO_WritePin(GPIOE, TIM1_CH3_PHASE_Pin|TIM1_CH4_PHASE_Pin|TIM2_CH1_PHASE_Pin|TIM8_CH4_PHASE_Pin
                          |TIM12_CH2_PHASE_Pin|TIM13_CH1_PHASE_Pin|TIM14_CH1_PHASE_Pin|TIM15_CH1_PHASE_Pin
                          |TIM1_CH1_PHASE_Pin|TIM1_CH2_PHASE_Pin, GPIO_PIN_RESET);

  /*Configure GPIO pin Output Level */
  HAL_GPIO_WritePin(GPIOC, TIM4_CH4_PHASE_Pin|TIM5_CH2_PHASE_Pin|TIM5_CH3_PHASE_Pin|TIM4_CH3_PHASE_Pin, GPIO_PIN_RESET);

  /*Configure GPIO pin Output Level */
  HAL_GPIO_WritePin(GPIOB, LED0_Pin|LED1_Pin|LED2_Pin|TIM4_CH1_PHASE_Pin
                          |TIM4_CH2_PHASE_Pin|SPI6_MUX_OE_n_Pin, GPIO_PIN_RESET);

  /*Configure GPIO pin Output Level */
  HAL_GPIO_WritePin(GPIOD, HRTIM_CHC1_PHASE_Pin|HRTIM_CHC2_PHASE_Pin|HRTIM_CHD1_PHASE_Pin|HRTIM_CHD2_PHASE_Pin
                          |TIM15_CH2_PHASE_Pin|TIM16_CH1_PHASE_Pin|HRTIM_CHA1_PHASE_Pin|HRTIM_CHA2_PHASE_Pin
                          |HRTIM_CHB1_PHASE_Pin|HRTIM_CHB2_PHASE_Pin, GPIO_PIN_RESET);

  /*Configure GPIO pin Output Level */
  HAL_GPIO_WritePin(ACTUATOR_ENABLE_MCU_GPIO_Port, ACTUATOR_ENABLE_MCU_Pin, GPIO_PIN_RESET);

  /*Configure GPIO pins : TIM1_CH3_PHASE_Pin TIM1_CH4_PHASE_Pin TIM2_CH1_PHASE_Pin TIM8_CH4_PHASE_Pin
                           TIM12_CH2_PHASE_Pin TIM13_CH1_PHASE_Pin TIM14_CH1_PHASE_Pin TIM15_CH1_PHASE_Pin
                           TIM1_CH1_PHASE_Pin TIM1_CH2_PHASE_Pin */
  GPIO_InitStruct.Pin = TIM1_CH3_PHASE_Pin|TIM1_CH4_PHASE_Pin|TIM2_CH1_PHASE_Pin|TIM8_CH4_PHASE_Pin
                          |TIM12_CH2_PHASE_Pin|TIM13_CH1_PHASE_Pin|TIM14_CH1_PHASE_Pin|TIM15_CH1_PHASE_Pin
                          |TIM1_CH1_PHASE_Pin|TIM1_CH2_PHASE_Pin;
  GPIO_InitStruct.Mode = GPIO_MODE_OUTPUT_PP;
  GPIO_InitStruct.Pull = GPIO_NOPULL;
  GPIO_InitStruct.Speed = GPIO_SPEED_FREQ_LOW;
  HAL_GPIO_Init(GPIOE, &GPIO_InitStruct);

  /*Configure GPIO pins : TIM4_CH4_PHASE_Pin TIM5_CH2_PHASE_Pin TIM5_CH3_PHASE_Pin TIM4_CH3_PHASE_Pin */
  GPIO_InitStruct.Pin = TIM4_CH4_PHASE_Pin|TIM5_CH2_PHASE_Pin|TIM5_CH3_PHASE_Pin|TIM4_CH3_PHASE_Pin;
  GPIO_InitStruct.Mode = GPIO_MODE_OUTPUT_PP;
  GPIO_InitStruct.Pull = GPIO_NOPULL;
  GPIO_InitStruct.Speed = GPIO_SPEED_FREQ_LOW;
  HAL_GPIO_Init(GPIOC, &GPIO_InitStruct);

  /*Configure GPIO pin : PC0 */
  GPIO_InitStruct.Pin = GPIO_PIN_0;
  GPIO_InitStruct.Mode = GPIO_MODE_ANALOG;
  GPIO_InitStruct.Pull = GPIO_NOPULL;
  HAL_GPIO_Init(GPIOC, &GPIO_InitStruct);

  /*Configure GPIO pins : PC3 LDC0_INTB_Pin */
  GPIO_InitStruct.Pin = GPIO_PIN_3|LDC0_INTB_Pin;
  GPIO_InitStruct.Mode = GPIO_MODE_INPUT;
  GPIO_InitStruct.Pull = GPIO_NOPULL;
  HAL_GPIO_Init(GPIOC, &GPIO_InitStruct);

  /*Configure GPIO pins : LED0_Pin LED1_Pin LED2_Pin TIM4_CH1_PHASE_Pin
                           TIM4_CH2_PHASE_Pin SPI6_MUX_OE_n_Pin */
  GPIO_InitStruct.Pin = LED0_Pin|LED1_Pin|LED2_Pin|TIM4_CH1_PHASE_Pin
                          |TIM4_CH2_PHASE_Pin|SPI6_MUX_OE_n_Pin;
  GPIO_InitStruct.Mode = GPIO_MODE_OUTPUT_PP;
  GPIO_InitStruct.Pull = GPIO_NOPULL;
  GPIO_InitStruct.Speed = GPIO_SPEED_FREQ_LOW;
  HAL_GPIO_Init(GPIOB, &GPIO_InitStruct);

  /*Configure GPIO pins : HRTIM_CHC1_PHASE_Pin HRTIM_CHC2_PHASE_Pin HRTIM_CHD1_PHASE_Pin HRTIM_CHD2_PHASE_Pin
                           TIM15_CH2_PHASE_Pin TIM16_CH1_PHASE_Pin HRTIM_CHA1_PHASE_Pin HRTIM_CHA2_PHASE_Pin
                           HRTIM_CHB1_PHASE_Pin HRTIM_CHB2_PHASE_Pin */
  GPIO_InitStruct.Pin = HRTIM_CHC1_PHASE_Pin|HRTIM_CHC2_PHASE_Pin|HRTIM_CHD1_PHASE_Pin|HRTIM_CHD2_PHASE_Pin
                          |TIM15_CH2_PHASE_Pin|TIM16_CH1_PHASE_Pin|HRTIM_CHA1_PHASE_Pin|HRTIM_CHA2_PHASE_Pin
                          |HRTIM_CHB1_PHASE_Pin|HRTIM_CHB2_PHASE_Pin;
  GPIO_InitStruct.Mode = GPIO_MODE_OUTPUT_PP;
  GPIO_InitStruct.Pull = GPIO_NOPULL;
  GPIO_InitStruct.Speed = GPIO_SPEED_FREQ_LOW;
  HAL_GPIO_Init(GPIOD, &GPIO_InitStruct);

  /*Configure GPIO pin : ACTUATOR_ENABLE_MCU_Pin */
  GPIO_InitStruct.Pin = ACTUATOR_ENABLE_MCU_Pin;
  GPIO_InitStruct.Mode = GPIO_MODE_OUTPUT_PP;
  GPIO_InitStruct.Pull = GPIO_NOPULL;
  GPIO_InitStruct.Speed = GPIO_SPEED_FREQ_LOW;
  HAL_GPIO_Init(ACTUATOR_ENABLE_MCU_GPIO_Port, &GPIO_InitStruct);

}

/* USER CODE BEGIN 4 */

/**
 * @function : HAL_TIM_PeriodElapsedCallback
 * @brief : reads the message from the rx buffer and puts it into module level message buffer
 * @param :  TIM_HandleTypeDef * htim
 * @return : none
 * @author : Aaron Hunter
 */
void HAL_TIM_PeriodElapsedCallback(TIM_HandleTypeDef *htim) {
	ctrl_tmr_expired = TRUE;
}

/**
 * @function : UART_parse_message
 * @brief : reads the message from the rx buffer and puts it into module level message buffer
 * @param :  none
 * @return : none
 * @author : Aaron Hunter
 */
static void UART_parse_message(void){
	char msg_type[] = "CMD";
	char response[BUFFER_LENGTH] = {0};
	char msg_buffer[BUFFER_LENGTH] = {0};

	char msg_hdr[CMD_HDR_LENGTH + 1] = {0};  // allocate an extra char for null termination
	int n_bytes = {0};
	int i;

	reading_rx_buffer = TRUE; // block RX interrupt while reading from the buffer

	int length = get_num_elements(rxbuf_p);
	for (i=0; i < length; i++){
		msg_buffer[i] = read_buffer(rxbuf_p);
	}

	reading_rx_buffer = FALSE;

	if (rx_collision == TRUE){
		UART4->CR1 |= USART_CR1_RXNEIE; // re-enable interrupt
		rx_collision = FALSE; // reset collision flag
	}

	memcpy(msg_hdr,msg_buffer,CMD_HDR_LENGTH*sizeof(uint8_t)); // Get the message type

	if(strcmp(msg_type,msg_hdr)==0 ){

//		memcpy(cmd_ref, &msg_buffer[CMD_HDR_LENGTH],NUM_ACTUATORS*(sizeof(int16_t)));  // get the data
		memcpy(reference.vals, &msg_buffer[CMD_HDR_LENGTH],NUM_ACTUATORS*(sizeof(int16_t)));  // get the data

		n_bytes = sprintf(response, " Values: %d, %d ", msg_buffer[length -3], msg_buffer[length -2]);
		UART_print(response, n_bytes);  // echo the first and last values
		new_cmd_ready = TRUE; // signal main to update the actuators with the new reference values
	} else {
		n_bytes = sprintf(response, " Unrecognized command: %s ", msg_hdr);
		UART_print(response, n_bytes);
	}

}

/**
 * @function : UART_print(char* buf, int length)
 * @brief : writes a buffer to the tx_buffer and triggers a UART TX
 * @param : buffer pointer
 * @param : buffer length
 * @return : none
 * @author : Aaron Hunter
 */
static void UART_print(char* buf, int length){
	int i;
	writing_tx_buffer = TRUE;  // block the TX interrupt while writing data to the buffer
	for (i = 0; i < length; i++){
		write_buffer(txbuf_p, buf[i]);
	}
	writing_tx_buffer = FALSE;
	/* enable interrupt to transmit message over the UART */
	if(tx_collision == TRUE) tx_collision = FALSE;
	UART4->CR1 |= USART_CR1_TXEIE;

}

/**
 * @function : init_channels
 * @brief : initializes all the PWM channels
 * @param :  none
 * @return : none
 * @author : Aaron Hunter
 */
static void init_channels(void){

	/* Timer 1 is the application timer and is interrupt-driven */
	HAL_TIM_Base_Start_IT(&htim1);
	HAL_TIM_PWM_Start(&htim1, TIM_CHANNEL_1);
	HAL_TIM_PWM_Start(&htim1, TIM_CHANNEL_2);
	HAL_TIM_PWM_Start(&htim1, TIM_CHANNEL_3);
	HAL_TIM_PWM_Start(&htim1, TIM_CHANNEL_4);

	/* Timer 2 */
	HAL_TIM_Base_Start(&htim2);
	HAL_TIM_PWM_Start(&htim2, TIM_CHANNEL_1);

	/* Timer 4 */
	HAL_TIM_Base_Start(&htim4);
	HAL_TIM_PWM_Start(&htim4, TIM_CHANNEL_1);
	HAL_TIM_PWM_Start(&htim4, TIM_CHANNEL_2);
	HAL_TIM_PWM_Start(&htim4, TIM_CHANNEL_3);
	HAL_TIM_PWM_Start(&htim4, TIM_CHANNEL_4);

	/* Timer 5 */
	HAL_TIM_Base_Start(&htim5);
	HAL_TIM_PWM_Start(&htim5, TIM_CHANNEL_2);
	HAL_TIM_PWM_Start(&htim5, TIM_CHANNEL_3);

	/* Timer 8 */
	HAL_TIM_Base_Start(&htim8);
	HAL_TIM_PWM_Start(&htim8, TIM_CHANNEL_4);

	/* Timer 12 */
	HAL_TIM_Base_Start(&htim12);
	HAL_TIM_PWM_Start(&htim12, TIM_CHANNEL_2);

	/* Timer 13 */
	HAL_TIM_Base_Start(&htim13);
	HAL_TIM_PWM_Start(&htim13, TIM_CHANNEL_1);

	/* Timer 14 */
	HAL_TIM_Base_Start(&htim14);
	HAL_TIM_PWM_Start(&htim14, TIM_CHANNEL_1);

	/* Timer 15 */
	HAL_TIM_Base_Start(&htim15);
	HAL_TIM_PWM_Start(&htim15, TIM_CHANNEL_1);
	HAL_TIM_PWM_Start(&htim15, TIM_CHANNEL_2);

	/* Timer 16 */
	HAL_TIM_Base_Start(&htim16);
	HAL_TIM_PWM_Start(&htim16, TIM_CHANNEL_1);

	/* High Resolution Timer */
	/* Enable outputs */
	HRTIM1->sCommonRegs.OENR = HRTIM_OENR_TA1OEN + HRTIM_OENR_TA2OEN + HRTIM_OENR_TB1OEN + HRTIM_OENR_TB2OEN
			+ HRTIM_OENR_TC1OEN + HRTIM_OENR_TC2OEN + HRTIM_OENR_TD1OEN + HRTIM_OENR_TD2OEN;
	/* Start Timer */
	HRTIM1->sMasterRegs.MCR = HRTIM_MCR_TACEN + HRTIM_MCR_TBCEN + HRTIM_MCR_TCCEN + HRTIM_MCR_TDCEN;

	/* Synchronize Timer 16 by resetting its clock to zero along with Timer 1 */
	/* all other timers except for 16 are updated in hardware using internal triggers */
	TIM1->CNT = 0;  // acts as the timing signal
	TIM16->CNT = 0; // reset timer 16 counter

}

/**
 * @function : init_actuators
 * @brief : Creates and populates actuator array
 * @param :  none
 * @return : none
 * @author : Aaron Hunter
 */
static void init_actuators(void){
	uint16_t duty = MINDUTYCYCLE;
	static int phase = GPIO_PIN_SET;
	int i = 0;

	actuator_init(&actuators[TIM1_CH1], TIM1_CH1, TIM1_CH1_PHASE_GPIO_Port, TIM1_CH1_PHASE_Pin,(volatile uint32_t *) &TIM1->CCR1);
	actuator_init(&actuators[TIM1_CH2], TIM1_CH2, TIM1_CH2_PHASE_GPIO_Port, TIM1_CH2_PHASE_Pin,(volatile uint32_t *) &TIM1->CCR2);
	actuator_init(&actuators[TIM1_CH3], TIM1_CH3, TIM1_CH3_PHASE_GPIO_Port, TIM1_CH3_PHASE_Pin,(volatile uint32_t *) &TIM1->CCR3);
	actuator_init(&actuators[TIM1_CH4], TIM1_CH4, TIM1_CH4_PHASE_GPIO_Port, TIM1_CH4_PHASE_Pin,(volatile uint32_t *) &TIM1->CCR4);
	actuator_init(&actuators[TIM2_CH1], TIM2_CH1, TIM2_CH1_PHASE_GPIO_Port, TIM2_CH1_PHASE_Pin,(volatile uint32_t *) &TIM2->CCR1);
	actuator_init(&actuators[TIM4_CH1], TIM4_CH1, TIM4_CH1_PHASE_GPIO_Port, TIM4_CH1_PHASE_Pin,(volatile uint32_t *) &TIM4->CCR1);
	actuator_init(&actuators[TIM4_CH2], TIM4_CH2, TIM4_CH2_PHASE_GPIO_Port, TIM4_CH2_PHASE_Pin,(volatile uint32_t *) &TIM4->CCR2);
	actuator_init(&actuators[TIM4_CH3], TIM4_CH3, TIM4_CH3_PHASE_GPIO_Port, TIM4_CH3_PHASE_Pin,(volatile uint32_t *) &TIM4->CCR3);
	actuator_init(&actuators[TIM4_CH4], TIM4_CH4, TIM4_CH4_PHASE_GPIO_Port, TIM4_CH4_PHASE_Pin,(volatile uint32_t *) &TIM4->CCR4);
	actuator_init(&actuators[TIM5_CH2], TIM5_CH2, TIM5_CH2_PHASE_GPIO_Port, TIM5_CH2_PHASE_Pin,(volatile uint32_t *) &TIM5->CCR2);
	actuator_init(&actuators[TIM5_CH3], TIM5_CH3, TIM5_CH3_PHASE_GPIO_Port, TIM5_CH3_PHASE_Pin,(volatile uint32_t *) &TIM5->CCR3);
	actuator_init(&actuators[TIM8_CH4], TIM8_CH4, TIM8_CH4_PHASE_GPIO_Port, TIM8_CH4_PHASE_Pin,(volatile uint32_t *) &TIM8->CCR4);
	actuator_init(&actuators[TIM12_CH2], TIM12_CH2, TIM12_CH2_PHASE_GPIO_Port, TIM12_CH2_PHASE_Pin,(volatile uint32_t *) &TIM12->CCR2);
	actuator_init(&actuators[TIM13_CH1], TIM13_CH1, TIM13_CH1_PHASE_GPIO_Port, TIM13_CH1_PHASE_Pin,(volatile uint32_t *) &TIM13->CCR1);
	actuator_init(&actuators[TIM14_CH1], TIM14_CH1, TIM14_CH1_PHASE_GPIO_Port, TIM14_CH1_PHASE_Pin,(volatile uint32_t *) &TIM14->CCR1);
	actuator_init(&actuators[TIM15_CH1], TIM15_CH1, TIM15_CH1_PHASE_GPIO_Port, TIM15_CH1_PHASE_Pin,(volatile uint32_t *) &TIM15->CCR1);
	actuator_init(&actuators[TIM15_CH2], TIM15_CH2, TIM15_CH2_PHASE_GPIO_Port, TIM15_CH2_PHASE_Pin,(volatile uint32_t *) &TIM15->CCR2);
	actuator_init(&actuators[TIM16_CH1], TIM16_CH1, TIM16_CH1_PHASE_GPIO_Port, TIM16_CH1_PHASE_Pin,(volatile uint32_t *) &TIM16->CCR1);
	actuator_init(&actuators[HRTIM_CHA1],HRTIM_CHA1, HRTIM_CHA1_PHASE_GPIO_Port, HRTIM_CHA1_PHASE_Pin,
				(volatile uint32_t *) &HRTIM1->sTimerxRegs[HRTIM_TIMERINDEX_TIMER_A].CMP1xR);
	actuator_init(&actuators[HRTIM_CHA2],HRTIM_CHA2, HRTIM_CHA2_PHASE_GPIO_Port, HRTIM_CHA2_PHASE_Pin,
				(volatile uint32_t *) &HRTIM1->sTimerxRegs[HRTIM_TIMERINDEX_TIMER_A].CMP2xR);
	actuator_init(&actuators[HRTIM_CHB1],HRTIM_CHB1, HRTIM_CHB1_PHASE_GPIO_Port, HRTIM_CHB1_PHASE_Pin,
				(volatile uint32_t *) &HRTIM1->sTimerxRegs[HRTIM_TIMERINDEX_TIMER_B].CMP1xR);
	actuator_init(&actuators[HRTIM_CHB2],HRTIM_CHB2, HRTIM_CHB2_PHASE_GPIO_Port, HRTIM_CHB2_PHASE_Pin,
				(volatile uint32_t *) &HRTIM1->sTimerxRegs[HRTIM_TIMERINDEX_TIMER_B].CMP2xR);
	actuator_init(&actuators[HRTIM_CHC1],HRTIM_CHC1, HRTIM_CHC1_PHASE_GPIO_Port, HRTIM_CHC1_PHASE_Pin,
				(volatile uint32_t *) &HRTIM1->sTimerxRegs[HRTIM_TIMERINDEX_TIMER_C].CMP1xR);
	actuator_init(&actuators[HRTIM_CHC2],HRTIM_CHC2, HRTIM_CHC2_PHASE_GPIO_Port, HRTIM_CHC2_PHASE_Pin,
				(volatile uint32_t *) &HRTIM1->sTimerxRegs[HRTIM_TIMERINDEX_TIMER_C].CMP2xR);
	actuator_init(&actuators[HRTIM_CHD1],HRTIM_CHD1, HRTIM_CHD1_PHASE_GPIO_Port, HRTIM_CHD1_PHASE_Pin,
				(volatile uint32_t *) &HRTIM1->sTimerxRegs[HRTIM_TIMERINDEX_TIMER_D].CMP1xR);
	actuator_init(&actuators[HRTIM_CHD2],HRTIM_CHD2, HRTIM_CHD2_PHASE_GPIO_Port, HRTIM_CHD2_PHASE_Pin,
				(volatile uint32_t *) &HRTIM1->sTimerxRegs[HRTIM_TIMERINDEX_TIMER_D].CMP2xR);

	/* initialize  the phase and dutycycle */
	for(i=0;i<NUM_ACTUATORS;i++){
		*(actuators[i].dutycycle) = duty;
		HAL_GPIO_WritePin(actuators[i].phase_port, actuators[i].phase_pin, phase);
	}
}

/**
 * @function : run_RX_state_machine
 * @brief : parses external command messages
 * @param byte : received byte
 * @return none
 * @author Aaron Hunter
 * */
void run_RX_state_machine(uint8_t byte){
	static serial_receive_state_t current_state= STORE_BYTE;
	serial_receive_state_t next_state;
	uint8_t end_bytes[2] = {0xe1, 0xe2};

	switch(current_state){
		case(STORE_BYTE):
			if(byte == end_bytes[0]){
				next_state = CHECK_FOR_END;
			}else{
				next_state = STORE_BYTE;
			}
			break;
		case(CHECK_FOR_END):
			if(byte == end_bytes[1]){
				msg_recvd = TRUE;
			}
			next_state = STORE_BYTE;
			break;
		default:
			break;
	}
	current_state = next_state;
}

/**
 * @function : run_SPI_RX_state_machine
 * @brief : parses external SPI command messages
 * @param byte : received byte
 * @return none
 * @author Aaron Hunter
 * */
void run_SPI_RX_state_machine(uint8_t byte){
	static serial_receive_state_t current_state= STORE_BYTE;
	serial_receive_state_t next_state;
	uint8_t end_bytes[2] = {0xe1, 0xe2};

	switch(current_state){
		case(STORE_BYTE):
			if(byte == end_bytes[0]){
				next_state = CHECK_FOR_END;
			}else{
				next_state = STORE_BYTE;
			}
			break;
		case(CHECK_FOR_END):
			if(byte == end_bytes[1]){
				spi_packet_rcvd = TRUE;
			}
			next_state = STORE_BYTE;
			break;
		default:
			break;
	}
	current_state = next_state;

}

/**
 * @function : update_commands
 * @brief : sets the new actuator command targets
 * @return none
 * @author Aaron Hunter
 */
static void update_commands(void){
	int i = 0;
	int8_t phase;
	uint16_t dutycycle;

	for(i = 0; i<NUM_ACTUATORS; i++){
//		phase = (cmd_ref[i]>0);  // phase is set to zero for negative commands, one for positive
//		dutycycle = calc_dutycycle(abs(cmd_ref[i])); // compute the dutycycle from the reference command
		phase = (reference.vals[i]>0);  // phase is set to zero for negative commands, one for positive
		dutycycle = calc_dutycycle(abs(reference.vals[i])); // compute the dutycycle from the reference command
		*(actuators[i].dutycycle) = dutycycle;  // set the duty cycle
		HAL_GPIO_WritePin(actuators[i].phase_port, actuators[i].phase_pin, phase);  // set the phase pin
	}
}

/**
 * @function calc_dutycycle(cmd)
 * @brief computes the dutycycle in counts from an actuator command in nanometers
 * @param cmd
 * @return dutycycle
 * @author Aaron Hunter
 */
uint16_t calc_dutycycle(int16_t cmd){
	uint16_t dutycycle = 0;
	uint16_t min_dutycycle = MINDUTYCYCLE;
	uint16_t max_dutycycle = MAXDUTYCYCLE;
	int scale_den = 10; //  scaling factor denominator
	int scale_num = 7; //  scaling factor numerator
	// apply lead filter
	dutycycle = (uint16_t)((abs((int)cmd) * scale_num)/scale_den);
	if(dutycycle < min_dutycycle) dutycycle = min_dutycycle;
	if(dutycycle > max_dutycycle) dutycycle = max_dutycycle;
	return dutycycle;
}

void HAL_SPI_TxRxCpltCallback(SPI_HandleTypeDef *hspi){

	int i={0};
	HAL_GPIO_WritePin(LED1_GPIO_Port, LED1_Pin,GPIO_PIN_SET); // indicate that the interrupt has fired

	for(i=0;i<SPI_MSG_SIZE;i++){
		SPI_TX_buffer[i] = SPI_RX_buffer[i];  // echo byte back to host
	}
	memcpy(SPI_TX_buffer,SPI_RX_buffer,SPI_MSG_SIZE*sizeof(uint8_t));

	spi_packet_rcvd = TRUE; // signal main that there is data to be processed
}

/* USER CODE END 4 */

void Error_Handler(void)
{
  __disable_irq();
  while (1)
  {
  }
}
